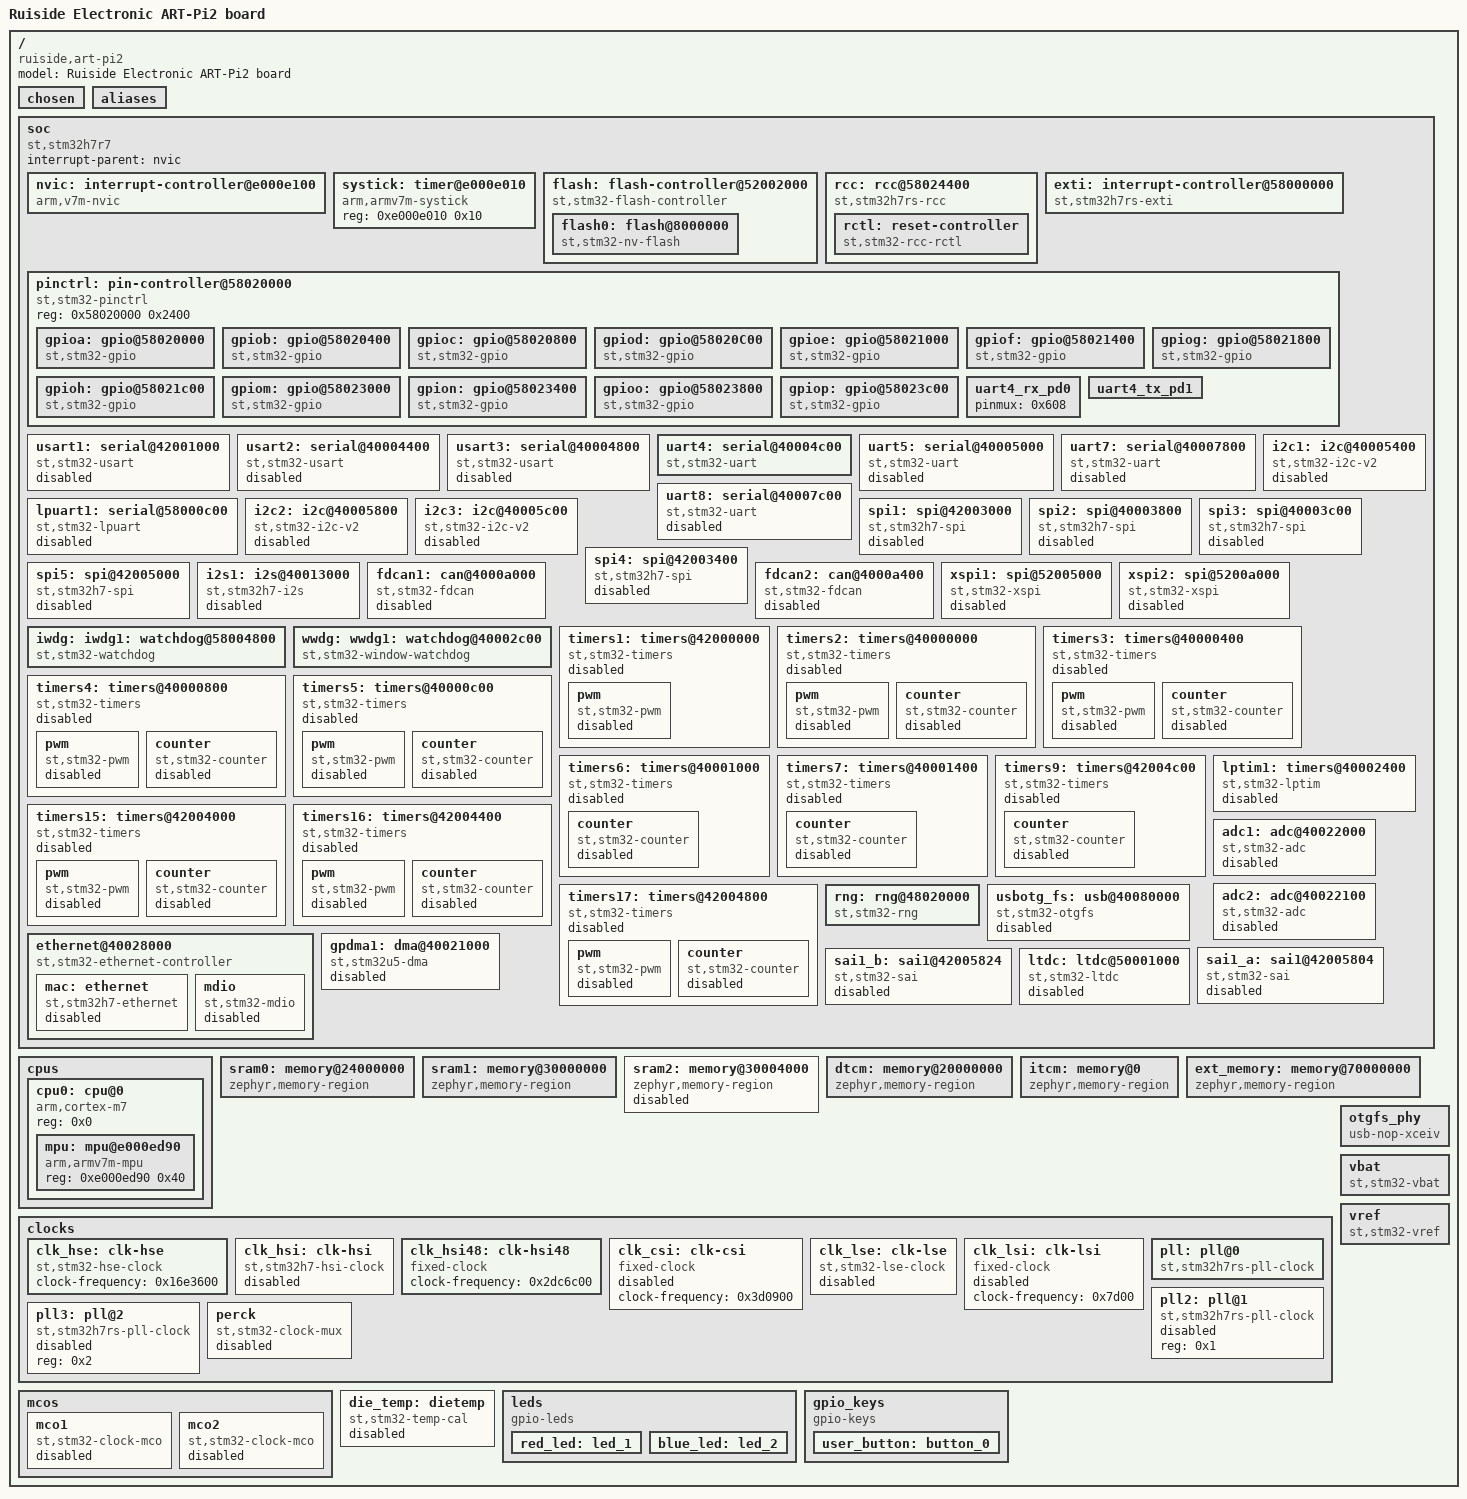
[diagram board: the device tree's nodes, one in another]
/dts-v1/;

/* node '/' defined in zephyr/dts/common/skeleton.dtsi:9 */
/ {
	#address-cells = < 0x1 >;                   /* in zephyr/dts/common/skeleton.dtsi:10 */
	#size-cells = < 0x1 >;                      /* in zephyr/dts/common/skeleton.dtsi:11 */
	model = "Ruiside Electronic ART-Pi2 board"; /* in zephyr/boards/ruiside/art_pi2/art_pi2.dts:13 */
	compatible = "ruiside,art-pi2";             /* in zephyr/boards/ruiside/art_pi2/art_pi2.dts:14 */

	/* node '/chosen' defined in zephyr/dts/common/skeleton.dtsi:13 */
	chosen {
		zephyr,entropy = &rng;            /* in zephyr/dts/arm/st/h7rs/stm32h7rs.dtsi:30 */
		zephyr,flash-controller = &flash; /* in zephyr/dts/arm/st/h7rs/stm32h7rs.dtsi:31 */
		zephyr,console = &uart4;          /* in zephyr/boards/ruiside/art_pi2/art_pi2.dts:17 */
		zephyr,shell-uart = &uart4;       /* in zephyr/boards/ruiside/art_pi2/art_pi2.dts:18 */
		zephyr,sram = &sram0;             /* in zephyr/boards/ruiside/art_pi2/art_pi2.dts:19 */
		zephyr,flash = &flash0;           /* in zephyr/boards/ruiside/art_pi2/art_pi2.dts:20 */
	};

	/* node '/aliases' defined in zephyr/dts/common/skeleton.dtsi:15 */
	aliases {
		led0 = &red_led;       /* in zephyr/boards/ruiside/art_pi2/art_pi2.dts:48 */
		led1 = &blue_led;      /* in zephyr/boards/ruiside/art_pi2/art_pi2.dts:49 */
		sw0 = &user_button;    /* in zephyr/boards/ruiside/art_pi2/art_pi2.dts:50 */
		watchdog0 = &iwdg;     /* in zephyr/boards/ruiside/art_pi2/art_pi2.dts:51 */
		die-temp0 = &die_temp; /* in zephyr/boards/ruiside/art_pi2/art_pi2.dts:52 */
		volt-sensor0 = &vref;  /* in zephyr/boards/ruiside/art_pi2/art_pi2.dts:53 */
		volt-sensor1 = &vbat;  /* in zephyr/boards/ruiside/art_pi2/art_pi2.dts:54 */
	};

	/* node '/soc' defined in zephyr/dts/arm/armv7-m.dtsi:6 */
	soc {
		#address-cells = < 0x1 >;     /* in zephyr/dts/arm/armv7-m.dtsi:7 */
		#size-cells = < 0x1 >;        /* in zephyr/dts/arm/armv7-m.dtsi:8 */
		interrupt-parent = < &nvic >; /* in zephyr/dts/arm/armv7-m.dtsi:10 */
		ranges;                       /* in zephyr/dts/arm/armv7-m.dtsi:11 */
		compatible = "st,stm32h7r7",
		             "st,stm32h7rs",
		             "simple-bus";    /* in zephyr/dts/arm/st/h7rs/stm32h7r7.dtsi:14 */

		/* node '/soc/interrupt-controller@e000e100' defined in zephyr/dts/arm/armv7-m.dtsi:13 */
		nvic: interrupt-controller@e000e100 {
			#address-cells = < 0x1 >;            /* in zephyr/dts/arm/armv7-m.dtsi:14 */
			compatible = "arm,v7m-nvic";         /* in zephyr/dts/arm/armv7-m.dtsi:15 */
			reg = < 0xe000e100 0xc00 >;          /* in zephyr/dts/arm/armv7-m.dtsi:16 */
			interrupt-controller;                /* in zephyr/dts/arm/armv7-m.dtsi:17 */
			#interrupt-cells = < 0x2 >;          /* in zephyr/dts/arm/armv7-m.dtsi:18 */
			arm,num-irq-priority-bits = < 0x4 >; /* in zephyr/dts/arm/st/h7rs/stm32h7rs.dtsi:985 */
			phandle = < 0x1 >;                   /* in zephyr/dts/arm/armv7-m.dtsi:10 */
		};

		/* node '/soc/timer@e000e010' defined in zephyr/dts/arm/armv7-m.dtsi:21 */
		systick: timer@e000e010 {
			compatible = "arm,armv7m-systick"; /* in zephyr/dts/arm/armv7-m.dtsi:22 */
			reg = < 0xe000e010 0x10 >;         /* in zephyr/dts/arm/armv7-m.dtsi:23 */
		};

		/* node '/soc/flash-controller@52002000' defined in zephyr/dts/arm/st/h7rs/stm32h7rs.dtsi:187 */
		flash: flash-controller@52002000 {
			compatible = "st,stm32-flash-controller",
			             "st,stm32h7-flash-controller"; /* in zephyr/dts/arm/st/h7rs/stm32h7rs.dtsi:188 */
			reg = < 0x52002000 0x400 >;                 /* in zephyr/dts/arm/st/h7rs/stm32h7rs.dtsi:189 */
			interrupts = < 0x8 0x0 >;                   /* in zephyr/dts/arm/st/h7rs/stm32h7rs.dtsi:190 */
			#address-cells = < 0x1 >;                   /* in zephyr/dts/arm/st/h7rs/stm32h7rs.dtsi:192 */
			#size-cells = < 0x1 >;                      /* in zephyr/dts/arm/st/h7rs/stm32h7rs.dtsi:193 */

			/* node '/soc/flash-controller@52002000/flash@8000000' defined in zephyr/dts/arm/st/h7rs/stm32h7rs.dtsi:195 */
			flash0: flash@8000000 {
				compatible = "st,stm32-nv-flash",
				             "soc-nv-flash";      /* in zephyr/dts/arm/st/h7rs/stm32h7rs.dtsi:196 */
				write-block-size = < 0x20 >;      /* in zephyr/dts/arm/st/h7rs/stm32h7rs.dtsi:197 */
				erase-block-size = < 0x2000 >;    /* in zephyr/dts/arm/st/h7rs/stm32h7rs.dtsi:198 */
				max-erase-time = < 0x3 >;         /* in zephyr/dts/arm/st/h7rs/stm32h7rs.dtsi:200 */
				reg = < 0x8000000 0x10000 >;      /* in zephyr/dts/arm/st/h7rs/stm32h7r7X8.dtsi:13 */
			};
		};

		/* node '/soc/rcc@58024400' defined in zephyr/dts/arm/st/h7rs/stm32h7rs.dtsi:204 */
		rcc: rcc@58024400 {
			compatible = "st,stm32h7rs-rcc"; /* in zephyr/dts/arm/st/h7rs/stm32h7rs.dtsi:205 */
			#clock-cells = < 0x2 >;          /* in zephyr/dts/arm/st/h7rs/stm32h7rs.dtsi:206 */
			reg = < 0x58024400 0x400 >;      /* in zephyr/dts/arm/st/h7rs/stm32h7rs.dtsi:207 */
			clocks = < &pll >;               /* in zephyr/boards/ruiside/art_pi2/art_pi2.dts:84 */
			clock-frequency = < 0xee6b280 >; /* in zephyr/boards/ruiside/art_pi2/art_pi2.dts:85 */
			dcpre = < 0x1 >;                 /* in zephyr/boards/ruiside/art_pi2/art_pi2.dts:86 */
			hpre = < 0x1 >;                  /* in zephyr/boards/ruiside/art_pi2/art_pi2.dts:87 */
			ppre1 = < 0x2 >;                 /* in zephyr/boards/ruiside/art_pi2/art_pi2.dts:88 */
			ppre2 = < 0x2 >;                 /* in zephyr/boards/ruiside/art_pi2/art_pi2.dts:89 */
			ppre4 = < 0x2 >;                 /* in zephyr/boards/ruiside/art_pi2/art_pi2.dts:90 */
			ppre5 = < 0x2 >;                 /* in zephyr/boards/ruiside/art_pi2/art_pi2.dts:91 */
			phandle = < 0x3 >;               /* in zephyr/dts/arm/st/h7rs/stm32h7rs.dtsi:221 */

			/* node '/soc/rcc@58024400/reset-controller' defined in zephyr/dts/arm/st/h7rs/stm32h7rs.dtsi:209 */
			rctl: reset-controller {
				compatible = "st,stm32-rcc-rctl"; /* in zephyr/dts/arm/st/h7rs/stm32h7rs.dtsi:210 */
				#reset-cells = < 0x1 >;           /* in zephyr/dts/arm/st/h7rs/stm32h7rs.dtsi:211 */
				phandle = < 0x4 >;                /* in zephyr/dts/arm/st/h7rs/stm32h7rs.dtsi:345 */
			};
		};

		/* node '/soc/interrupt-controller@58000000' defined in zephyr/dts/arm/st/h7rs/stm32h7rs.dtsi:215 */
		exti: interrupt-controller@58000000 {
			compatible = "st,stm32h7rs-exti",
			             "st,stm32-exti";     /* in zephyr/dts/arm/st/h7rs/stm32h7rs.dtsi:216 */
			interrupt-controller;             /* in zephyr/dts/arm/st/h7rs/stm32h7rs.dtsi:217 */
			#interrupt-cells = < 0x1 >;       /* in zephyr/dts/arm/st/h7rs/stm32h7rs.dtsi:218 */
			#address-cells = < 0x0 >;         /* in zephyr/dts/arm/st/h7rs/stm32h7rs.dtsi:219 */
			reg = < 0x58000000 0x400 >;       /* in zephyr/dts/arm/st/h7rs/stm32h7rs.dtsi:220 */
			clocks = < &rcc 0x154 0x2 >;      /* in zephyr/dts/arm/st/h7rs/stm32h7rs.dtsi:221 */
			num-lines = < 0x40 >;             /* in zephyr/dts/arm/st/h7rs/stm32h7rs.dtsi:223 */
			interrupts = < 0x10 0x0 >,
			             < 0x11 0x0 >,
			             < 0x12 0x0 >,
			             < 0x13 0x0 >,
			             < 0x14 0x0 >,
			             < 0x15 0x0 >,
			             < 0x16 0x0 >,
			             < 0x17 0x0 >,
			             < 0x18 0x0 >,
			             < 0x19 0x0 >,
			             < 0x1a 0x0 >,
			             < 0x1b 0x0 >,
			             < 0x1c 0x0 >,
			             < 0x1d 0x0 >,
			             < 0x1e 0x0 >,
			             < 0x1f 0x0 >;        /* in zephyr/dts/arm/st/h7rs/stm32h7rs.dtsi:224 */
			interrupt-names = "line0",
			                  "line1",
			                  "line2",
			                  "line3",
			                  "line4",
			                  "line5",
			                  "line6",
			                  "line7",
			                  "line8",
			                  "line9",
			                  "line10",
			                  "line11",
			                  "line12",
			                  "line13",
			                  "line14",
			                  "line15";       /* in zephyr/dts/arm/st/h7rs/stm32h7rs.dtsi:228 */
			line-ranges = < 0x0 0x1 >,
			              < 0x1 0x1 >,
			              < 0x2 0x1 >,
			              < 0x3 0x1 >,
			              < 0x4 0x1 >,
			              < 0x5 0x1 >,
			              < 0x6 0x1 >,
			              < 0x7 0x1 >,
			              < 0x8 0x1 >,
			              < 0x9 0x1 >,
			              < 0xa 0x1 >,
			              < 0xb 0x1 >,
			              < 0xc 0x1 >,
			              < 0xd 0x1 >,
			              < 0xe 0x1 >,
			              < 0xf 0x1 >;        /* in zephyr/dts/arm/st/h7rs/stm32h7rs.dtsi:232 */
		};

		/* node '/soc/pin-controller@58020000' defined in zephyr/dts/arm/st/h7rs/stm32h7rs.dtsi:238 */
		pinctrl: pin-controller@58020000 {
			compatible = "st,stm32-pinctrl"; /* in zephyr/dts/arm/st/h7rs/stm32h7rs.dtsi:239 */
			#address-cells = < 0x1 >;        /* in zephyr/dts/arm/st/h7rs/stm32h7rs.dtsi:240 */
			#size-cells = < 0x1 >;           /* in zephyr/dts/arm/st/h7rs/stm32h7rs.dtsi:241 */
			reg = < 0x58020000 0x2400 >;     /* in zephyr/dts/arm/st/h7rs/stm32h7rs.dtsi:242 */

			/* node '/soc/pin-controller@58020000/gpio@58020000' defined in zephyr/dts/arm/st/h7rs/stm32h7rs.dtsi:244 */
			gpioa: gpio@58020000 {
				compatible = "st,stm32-gpio"; /* in zephyr/dts/arm/st/h7rs/stm32h7rs.dtsi:245 */
				gpio-controller;              /* in zephyr/dts/arm/st/h7rs/stm32h7rs.dtsi:246 */
				#gpio-cells = < 0x2 >;        /* in zephyr/dts/arm/st/h7rs/stm32h7rs.dtsi:247 */
				reg = < 0x58020000 0x400 >;   /* in zephyr/dts/arm/st/h7rs/stm32h7rs.dtsi:248 */
				clocks = < &rcc 0x140 0x1 >;  /* in zephyr/dts/arm/st/h7rs/stm32h7rs.dtsi:249 */
			};

			/* node '/soc/pin-controller@58020000/gpio@58020400' defined in zephyr/dts/arm/st/h7rs/stm32h7rs.dtsi:252 */
			gpiob: gpio@58020400 {
				compatible = "st,stm32-gpio"; /* in zephyr/dts/arm/st/h7rs/stm32h7rs.dtsi:253 */
				gpio-controller;              /* in zephyr/dts/arm/st/h7rs/stm32h7rs.dtsi:254 */
				#gpio-cells = < 0x2 >;        /* in zephyr/dts/arm/st/h7rs/stm32h7rs.dtsi:255 */
				reg = < 0x58020400 0x400 >;   /* in zephyr/dts/arm/st/h7rs/stm32h7rs.dtsi:256 */
				clocks = < &rcc 0x140 0x2 >;  /* in zephyr/dts/arm/st/h7rs/stm32h7rs.dtsi:257 */
			};

			/* node '/soc/pin-controller@58020000/gpio@58020800' defined in zephyr/dts/arm/st/h7rs/stm32h7rs.dtsi:260 */
			gpioc: gpio@58020800 {
				compatible = "st,stm32-gpio"; /* in zephyr/dts/arm/st/h7rs/stm32h7rs.dtsi:261 */
				gpio-controller;              /* in zephyr/dts/arm/st/h7rs/stm32h7rs.dtsi:262 */
				#gpio-cells = < 0x2 >;        /* in zephyr/dts/arm/st/h7rs/stm32h7rs.dtsi:263 */
				reg = < 0x58020800 0x400 >;   /* in zephyr/dts/arm/st/h7rs/stm32h7rs.dtsi:264 */
				clocks = < &rcc 0x140 0x4 >;  /* in zephyr/dts/arm/st/h7rs/stm32h7rs.dtsi:265 */
				phandle = < 0xd >;            /* in zephyr/boards/ruiside/art_pi2/art_pi2.dts:42 */
			};

			/* node '/soc/pin-controller@58020000/gpio@58020C00' defined in zephyr/dts/arm/st/h7rs/stm32h7rs.dtsi:268 */
			gpiod: gpio@58020C00 {
				compatible = "st,stm32-gpio"; /* in zephyr/dts/arm/st/h7rs/stm32h7rs.dtsi:269 */
				gpio-controller;              /* in zephyr/dts/arm/st/h7rs/stm32h7rs.dtsi:270 */
				#gpio-cells = < 0x2 >;        /* in zephyr/dts/arm/st/h7rs/stm32h7rs.dtsi:271 */
				reg = < 0x58020c00 0x400 >;   /* in zephyr/dts/arm/st/h7rs/stm32h7rs.dtsi:272 */
				clocks = < &rcc 0x140 0x8 >;  /* in zephyr/dts/arm/st/h7rs/stm32h7rs.dtsi:273 */
			};

			/* node '/soc/pin-controller@58020000/gpio@58021000' defined in zephyr/dts/arm/st/h7rs/stm32h7rs.dtsi:276 */
			gpioe: gpio@58021000 {
				compatible = "st,stm32-gpio"; /* in zephyr/dts/arm/st/h7rs/stm32h7rs.dtsi:277 */
				gpio-controller;              /* in zephyr/dts/arm/st/h7rs/stm32h7rs.dtsi:278 */
				#gpio-cells = < 0x2 >;        /* in zephyr/dts/arm/st/h7rs/stm32h7rs.dtsi:279 */
				reg = < 0x58021000 0x400 >;   /* in zephyr/dts/arm/st/h7rs/stm32h7rs.dtsi:280 */
				clocks = < &rcc 0x140 0x10 >; /* in zephyr/dts/arm/st/h7rs/stm32h7rs.dtsi:281 */
			};

			/* node '/soc/pin-controller@58020000/gpio@58021400' defined in zephyr/dts/arm/st/h7rs/stm32h7rs.dtsi:284 */
			gpiof: gpio@58021400 {
				compatible = "st,stm32-gpio"; /* in zephyr/dts/arm/st/h7rs/stm32h7rs.dtsi:285 */
				gpio-controller;              /* in zephyr/dts/arm/st/h7rs/stm32h7rs.dtsi:286 */
				#gpio-cells = < 0x2 >;        /* in zephyr/dts/arm/st/h7rs/stm32h7rs.dtsi:287 */
				reg = < 0x58021400 0x400 >;   /* in zephyr/dts/arm/st/h7rs/stm32h7rs.dtsi:288 */
				clocks = < &rcc 0x140 0x20 >; /* in zephyr/dts/arm/st/h7rs/stm32h7rs.dtsi:289 */
			};

			/* node '/soc/pin-controller@58020000/gpio@58021800' defined in zephyr/dts/arm/st/h7rs/stm32h7rs.dtsi:292 */
			gpiog: gpio@58021800 {
				compatible = "st,stm32-gpio"; /* in zephyr/dts/arm/st/h7rs/stm32h7rs.dtsi:293 */
				gpio-controller;              /* in zephyr/dts/arm/st/h7rs/stm32h7rs.dtsi:294 */
				#gpio-cells = < 0x2 >;        /* in zephyr/dts/arm/st/h7rs/stm32h7rs.dtsi:295 */
				reg = < 0x58021800 0x400 >;   /* in zephyr/dts/arm/st/h7rs/stm32h7rs.dtsi:296 */
				clocks = < &rcc 0x140 0x40 >; /* in zephyr/dts/arm/st/h7rs/stm32h7rs.dtsi:297 */
			};

			/* node '/soc/pin-controller@58020000/gpio@58021c00' defined in zephyr/dts/arm/st/h7rs/stm32h7rs.dtsi:300 */
			gpioh: gpio@58021c00 {
				compatible = "st,stm32-gpio"; /* in zephyr/dts/arm/st/h7rs/stm32h7rs.dtsi:301 */
				gpio-controller;              /* in zephyr/dts/arm/st/h7rs/stm32h7rs.dtsi:302 */
				#gpio-cells = < 0x2 >;        /* in zephyr/dts/arm/st/h7rs/stm32h7rs.dtsi:303 */
				reg = < 0x58021c00 0x400 >;   /* in zephyr/dts/arm/st/h7rs/stm32h7rs.dtsi:304 */
				clocks = < &rcc 0x140 0x80 >; /* in zephyr/dts/arm/st/h7rs/stm32h7rs.dtsi:305 */
			};

			/* node '/soc/pin-controller@58020000/gpio@58023000' defined in zephyr/dts/arm/st/h7rs/stm32h7rs.dtsi:308 */
			gpiom: gpio@58023000 {
				compatible = "st,stm32-gpio";   /* in zephyr/dts/arm/st/h7rs/stm32h7rs.dtsi:309 */
				gpio-controller;                /* in zephyr/dts/arm/st/h7rs/stm32h7rs.dtsi:310 */
				#gpio-cells = < 0x2 >;          /* in zephyr/dts/arm/st/h7rs/stm32h7rs.dtsi:311 */
				reg = < 0x58023000 0x400 >;     /* in zephyr/dts/arm/st/h7rs/stm32h7rs.dtsi:312 */
				clocks = < &rcc 0x140 0x1000 >; /* in zephyr/dts/arm/st/h7rs/stm32h7rs.dtsi:313 */
			};

			/* node '/soc/pin-controller@58020000/gpio@58023400' defined in zephyr/dts/arm/st/h7rs/stm32h7rs.dtsi:316 */
			gpion: gpio@58023400 {
				compatible = "st,stm32-gpio";   /* in zephyr/dts/arm/st/h7rs/stm32h7rs.dtsi:317 */
				gpio-controller;                /* in zephyr/dts/arm/st/h7rs/stm32h7rs.dtsi:318 */
				#gpio-cells = < 0x2 >;          /* in zephyr/dts/arm/st/h7rs/stm32h7rs.dtsi:319 */
				reg = < 0x58023400 0x400 >;     /* in zephyr/dts/arm/st/h7rs/stm32h7rs.dtsi:320 */
				clocks = < &rcc 0x140 0x2000 >; /* in zephyr/dts/arm/st/h7rs/stm32h7rs.dtsi:321 */
			};

			/* node '/soc/pin-controller@58020000/gpio@58023800' defined in zephyr/dts/arm/st/h7rs/stm32h7rs.dtsi:324 */
			gpioo: gpio@58023800 {
				compatible = "st,stm32-gpio";   /* in zephyr/dts/arm/st/h7rs/stm32h7rs.dtsi:325 */
				gpio-controller;                /* in zephyr/dts/arm/st/h7rs/stm32h7rs.dtsi:326 */
				#gpio-cells = < 0x2 >;          /* in zephyr/dts/arm/st/h7rs/stm32h7rs.dtsi:327 */
				reg = < 0x58023800 0x400 >;     /* in zephyr/dts/arm/st/h7rs/stm32h7rs.dtsi:328 */
				clocks = < &rcc 0x140 0x4000 >; /* in zephyr/dts/arm/st/h7rs/stm32h7rs.dtsi:329 */
				phandle = < 0xc >;              /* in zephyr/boards/ruiside/art_pi2/art_pi2.dts:27 */
			};

			/* node '/soc/pin-controller@58020000/gpio@58023c00' defined in zephyr/dts/arm/st/h7rs/stm32h7rs.dtsi:332 */
			gpiop: gpio@58023c00 {
				compatible = "st,stm32-gpio";   /* in zephyr/dts/arm/st/h7rs/stm32h7rs.dtsi:333 */
				gpio-controller;                /* in zephyr/dts/arm/st/h7rs/stm32h7rs.dtsi:334 */
				#gpio-cells = < 0x2 >;          /* in zephyr/dts/arm/st/h7rs/stm32h7rs.dtsi:335 */
				reg = < 0x58023c00 0x400 >;     /* in zephyr/dts/arm/st/h7rs/stm32h7rs.dtsi:336 */
				clocks = < &rcc 0x140 0x8000 >; /* in zephyr/dts/arm/st/h7rs/stm32h7rs.dtsi:337 */
			};

			/* node '/soc/pin-controller@58020000/uart4_rx_pd0' defined in modules/hal/stm32/dts/st/h7/stm32h7r7l8hxh-pinctrl.dtsi:3787 */
			uart4_rx_pd0: uart4_rx_pd0 {
				pinmux = < 0x608 >; /* in modules/hal/stm32/dts/st/h7/stm32h7r7l8hxh-pinctrl.dtsi:3788 */
				phandle = < 0x6 >;  /* in zephyr/boards/ruiside/art_pi2/art_pi2.dts:95 */
			};

			/* node '/soc/pin-controller@58020000/uart4_tx_pd1' defined in modules/hal/stm32/dts/st/h7/stm32h7r7l8hxh-pinctrl.dtsi:3899 */
			uart4_tx_pd1: uart4_tx_pd1 {
				pinmux = < 0x628 >; /* in modules/hal/stm32/dts/st/h7/stm32h7r7l8hxh-pinctrl.dtsi:3900 */
				bias-pull-up;       /* in modules/hal/stm32/dts/st/h7/stm32h7r7l8hxh-pinctrl.dtsi:3901 */
				phandle = < 0x5 >;  /* in zephyr/boards/ruiside/art_pi2/art_pi2.dts:95 */
			};
		};

		/* node '/soc/serial@42001000' defined in zephyr/dts/arm/st/h7rs/stm32h7rs.dtsi:341 */
		usart1: serial@42001000 {
			compatible = "st,stm32-usart",
			             "st,stm32-uart";  /* in zephyr/dts/arm/st/h7rs/stm32h7rs.dtsi:342 */
			reg = < 0x42001000 0x400 >;    /* in zephyr/dts/arm/st/h7rs/stm32h7rs.dtsi:343 */
			clocks = < &rcc 0x150 0x10 >;  /* in zephyr/dts/arm/st/h7rs/stm32h7rs.dtsi:344 */
			resets = < &rctl 0x1304 >;     /* in zephyr/dts/arm/st/h7rs/stm32h7rs.dtsi:345 */
			interrupts = < 0x52 0x0 >;     /* in zephyr/dts/arm/st/h7rs/stm32h7rs.dtsi:346 */
			status = "disabled";           /* in zephyr/dts/arm/st/h7rs/stm32h7rs.dtsi:347 */
		};

		/* node '/soc/serial@40004400' defined in zephyr/dts/arm/st/h7rs/stm32h7rs.dtsi:350 */
		usart2: serial@40004400 {
			compatible = "st,stm32-usart",
			             "st,stm32-uart";    /* in zephyr/dts/arm/st/h7rs/stm32h7rs.dtsi:351 */
			reg = < 0x40004400 0x400 >;      /* in zephyr/dts/arm/st/h7rs/stm32h7rs.dtsi:352 */
			clocks = < &rcc 0x148 0x20000 >; /* in zephyr/dts/arm/st/h7rs/stm32h7rs.dtsi:353 */
			resets = < &rctl 0x1211 >;       /* in zephyr/dts/arm/st/h7rs/stm32h7rs.dtsi:354 */
			interrupts = < 0x53 0x0 >;       /* in zephyr/dts/arm/st/h7rs/stm32h7rs.dtsi:355 */
			status = "disabled";             /* in zephyr/dts/arm/st/h7rs/stm32h7rs.dtsi:356 */
		};

		/* node '/soc/serial@40004800' defined in zephyr/dts/arm/st/h7rs/stm32h7rs.dtsi:359 */
		usart3: serial@40004800 {
			compatible = "st,stm32-usart",
			             "st,stm32-uart";    /* in zephyr/dts/arm/st/h7rs/stm32h7rs.dtsi:360 */
			reg = < 0x40004800 0x400 >;      /* in zephyr/dts/arm/st/h7rs/stm32h7rs.dtsi:361 */
			clocks = < &rcc 0x148 0x40000 >; /* in zephyr/dts/arm/st/h7rs/stm32h7rs.dtsi:362 */
			resets = < &rctl 0x1212 >;       /* in zephyr/dts/arm/st/h7rs/stm32h7rs.dtsi:363 */
			interrupts = < 0x54 0x0 >;       /* in zephyr/dts/arm/st/h7rs/stm32h7rs.dtsi:364 */
			status = "disabled";             /* in zephyr/dts/arm/st/h7rs/stm32h7rs.dtsi:365 */
		};

		/* node '/soc/serial@40004c00' defined in zephyr/dts/arm/st/h7rs/stm32h7rs.dtsi:368 */
		uart4: serial@40004c00 {
			compatible = "st,stm32-uart";                /* in zephyr/dts/arm/st/h7rs/stm32h7rs.dtsi:369 */
			reg = < 0x40004c00 0x400 >;                  /* in zephyr/dts/arm/st/h7rs/stm32h7rs.dtsi:370 */
			clocks = < &rcc 0x148 0x80000 >;             /* in zephyr/dts/arm/st/h7rs/stm32h7rs.dtsi:371 */
			resets = < &rctl 0x1213 >;                   /* in zephyr/dts/arm/st/h7rs/stm32h7rs.dtsi:372 */
			interrupts = < 0x55 0x0 >;                   /* in zephyr/dts/arm/st/h7rs/stm32h7rs.dtsi:373 */
			pinctrl-0 = < &uart4_tx_pd1 &uart4_rx_pd0 >; /* in zephyr/boards/ruiside/art_pi2/art_pi2.dts:95 */
			pinctrl-names = "default";                   /* in zephyr/boards/ruiside/art_pi2/art_pi2.dts:96 */
			current-speed = < 0x1c200 >;                 /* in zephyr/boards/ruiside/art_pi2/art_pi2.dts:97 */
			status = "okay";                             /* in zephyr/boards/ruiside/art_pi2/art_pi2.dts:98 */
		};

		/* node '/soc/serial@40005000' defined in zephyr/dts/arm/st/h7rs/stm32h7rs.dtsi:377 */
		uart5: serial@40005000 {
			compatible = "st,stm32-uart";     /* in zephyr/dts/arm/st/h7rs/stm32h7rs.dtsi:378 */
			reg = < 0x40005000 0x400 >;       /* in zephyr/dts/arm/st/h7rs/stm32h7rs.dtsi:379 */
			clocks = < &rcc 0x148 0x100000 >; /* in zephyr/dts/arm/st/h7rs/stm32h7rs.dtsi:380 */
			resets = < &rctl 0x1214 >;        /* in zephyr/dts/arm/st/h7rs/stm32h7rs.dtsi:381 */
			interrupts = < 0x56 0x0 >;        /* in zephyr/dts/arm/st/h7rs/stm32h7rs.dtsi:382 */
			status = "disabled";              /* in zephyr/dts/arm/st/h7rs/stm32h7rs.dtsi:383 */
		};

		/* node '/soc/serial@40007800' defined in zephyr/dts/arm/st/h7rs/stm32h7rs.dtsi:386 */
		uart7: serial@40007800 {
			compatible = "st,stm32-uart";       /* in zephyr/dts/arm/st/h7rs/stm32h7rs.dtsi:387 */
			reg = < 0x40007800 0x400 >;         /* in zephyr/dts/arm/st/h7rs/stm32h7rs.dtsi:388 */
			clocks = < &rcc 0x148 0x40000000 >; /* in zephyr/dts/arm/st/h7rs/stm32h7rs.dtsi:389 */
			resets = < &rctl 0x121e >;          /* in zephyr/dts/arm/st/h7rs/stm32h7rs.dtsi:390 */
			interrupts = < 0x57 0x0 >;          /* in zephyr/dts/arm/st/h7rs/stm32h7rs.dtsi:391 */
			status = "disabled";                /* in zephyr/dts/arm/st/h7rs/stm32h7rs.dtsi:392 */
		};

		/* node '/soc/serial@40007c00' defined in zephyr/dts/arm/st/h7rs/stm32h7rs.dtsi:395 */
		uart8: serial@40007c00 {
			compatible = "st,stm32-uart";       /* in zephyr/dts/arm/st/h7rs/stm32h7rs.dtsi:396 */
			reg = < 0x40007c00 0x400 >;         /* in zephyr/dts/arm/st/h7rs/stm32h7rs.dtsi:397 */
			clocks = < &rcc 0x148 0x80000000 >; /* in zephyr/dts/arm/st/h7rs/stm32h7rs.dtsi:398 */
			resets = < &rctl 0x121f >;          /* in zephyr/dts/arm/st/h7rs/stm32h7rs.dtsi:399 */
			interrupts = < 0x58 0x0 >;          /* in zephyr/dts/arm/st/h7rs/stm32h7rs.dtsi:400 */
			status = "disabled";                /* in zephyr/dts/arm/st/h7rs/stm32h7rs.dtsi:401 */
		};

		/* node '/soc/serial@58000c00' defined in zephyr/dts/arm/st/h7rs/stm32h7rs.dtsi:404 */
		lpuart1: serial@58000c00 {
			compatible = "st,stm32-lpuart",
			             "st,stm32-uart";   /* in zephyr/dts/arm/st/h7rs/stm32h7rs.dtsi:405 */
			reg = < 0x58000c00 0x400 >;     /* in zephyr/dts/arm/st/h7rs/stm32h7rs.dtsi:406 */
			clocks = < &rcc 0x154 0x8 >;    /* in zephyr/dts/arm/st/h7rs/stm32h7rs.dtsi:407 */
			resets = < &rctl 0x1383 >;      /* in zephyr/dts/arm/st/h7rs/stm32h7rs.dtsi:408 */
			interrupts = < 0x83 0x0 >;      /* in zephyr/dts/arm/st/h7rs/stm32h7rs.dtsi:409 */
			status = "disabled";            /* in zephyr/dts/arm/st/h7rs/stm32h7rs.dtsi:410 */
		};

		/* node '/soc/i2c@40005400' defined in zephyr/dts/arm/st/h7rs/stm32h7rs.dtsi:413 */
		i2c1: i2c@40005400 {
			compatible = "st,stm32-i2c-v2";   /* in zephyr/dts/arm/st/h7rs/stm32h7rs.dtsi:414 */
			clock-frequency = < 0x186a0 >;    /* in zephyr/dts/arm/st/h7rs/stm32h7rs.dtsi:415 */
			#address-cells = < 0x1 >;         /* in zephyr/dts/arm/st/h7rs/stm32h7rs.dtsi:416 */
			#size-cells = < 0x0 >;            /* in zephyr/dts/arm/st/h7rs/stm32h7rs.dtsi:417 */
			reg = < 0x40005400 0x400 >;       /* in zephyr/dts/arm/st/h7rs/stm32h7rs.dtsi:418 */
			clocks = < &rcc 0x148 0x200000 >; /* in zephyr/dts/arm/st/h7rs/stm32h7rs.dtsi:419 */
			interrupts = < 0x4c 0x0 >,
			             < 0x4d 0x0 >;        /* in zephyr/dts/arm/st/h7rs/stm32h7rs.dtsi:420 */
			interrupt-names = "event",
			                  "error";        /* in zephyr/dts/arm/st/h7rs/stm32h7rs.dtsi:421 */
			status = "disabled";              /* in zephyr/dts/arm/st/h7rs/stm32h7rs.dtsi:422 */
		};

		/* node '/soc/i2c@40005800' defined in zephyr/dts/arm/st/h7rs/stm32h7rs.dtsi:425 */
		i2c2: i2c@40005800 {
			compatible = "st,stm32-i2c-v2";   /* in zephyr/dts/arm/st/h7rs/stm32h7rs.dtsi:426 */
			clock-frequency = < 0x186a0 >;    /* in zephyr/dts/arm/st/h7rs/stm32h7rs.dtsi:427 */
			#address-cells = < 0x1 >;         /* in zephyr/dts/arm/st/h7rs/stm32h7rs.dtsi:428 */
			#size-cells = < 0x0 >;            /* in zephyr/dts/arm/st/h7rs/stm32h7rs.dtsi:429 */
			reg = < 0x40005800 0x400 >;       /* in zephyr/dts/arm/st/h7rs/stm32h7rs.dtsi:430 */
			clocks = < &rcc 0x148 0x400000 >; /* in zephyr/dts/arm/st/h7rs/stm32h7rs.dtsi:431 */
			interrupts = < 0x4e 0x0 >,
			             < 0x4f 0x0 >;        /* in zephyr/dts/arm/st/h7rs/stm32h7rs.dtsi:432 */
			interrupt-names = "event",
			                  "error";        /* in zephyr/dts/arm/st/h7rs/stm32h7rs.dtsi:433 */
			status = "disabled";              /* in zephyr/dts/arm/st/h7rs/stm32h7rs.dtsi:434 */
		};

		/* node '/soc/i2c@40005c00' defined in zephyr/dts/arm/st/h7rs/stm32h7rs.dtsi:437 */
		i2c3: i2c@40005c00 {
			compatible = "st,stm32-i2c-v2";   /* in zephyr/dts/arm/st/h7rs/stm32h7rs.dtsi:438 */
			clock-frequency = < 0x186a0 >;    /* in zephyr/dts/arm/st/h7rs/stm32h7rs.dtsi:439 */
			#address-cells = < 0x1 >;         /* in zephyr/dts/arm/st/h7rs/stm32h7rs.dtsi:440 */
			#size-cells = < 0x0 >;            /* in zephyr/dts/arm/st/h7rs/stm32h7rs.dtsi:441 */
			reg = < 0x40005c00 0x400 >;       /* in zephyr/dts/arm/st/h7rs/stm32h7rs.dtsi:442 */
			clocks = < &rcc 0x148 0x800000 >; /* in zephyr/dts/arm/st/h7rs/stm32h7rs.dtsi:443 */
			interrupts = < 0x50 0x0 >,
			             < 0x51 0x0 >;        /* in zephyr/dts/arm/st/h7rs/stm32h7rs.dtsi:444 */
			interrupt-names = "event",
			                  "error";        /* in zephyr/dts/arm/st/h7rs/stm32h7rs.dtsi:445 */
			status = "disabled";              /* in zephyr/dts/arm/st/h7rs/stm32h7rs.dtsi:446 */
		};

		/* node '/soc/spi@42003000' defined in zephyr/dts/arm/st/h7rs/stm32h7rs.dtsi:449 */
		spi1: spi@42003000 {
			compatible = "st,stm32h7-spi",
			             "st,stm32-spi-fifo",
			             "st,stm32-spi";      /* in zephyr/dts/arm/st/h7rs/stm32h7rs.dtsi:450 */
			#address-cells = < 0x1 >;         /* in zephyr/dts/arm/st/h7rs/stm32h7rs.dtsi:451 */
			#size-cells = < 0x0 >;            /* in zephyr/dts/arm/st/h7rs/stm32h7rs.dtsi:452 */
			reg = < 0x42003000 0x400 >;       /* in zephyr/dts/arm/st/h7rs/stm32h7rs.dtsi:453 */
			clocks = < &rcc 0x150 0x1000 >,
			         < &rcc 0x9 0x480054 >;   /* in zephyr/dts/arm/st/h7rs/stm32h7rs.dtsi:454 */
			interrupts = < 0x3a 0x0 >;        /* in zephyr/dts/arm/st/h7rs/stm32h7rs.dtsi:456 */
			status = "disabled";              /* in zephyr/dts/arm/st/h7rs/stm32h7rs.dtsi:457 */
		};

		/* node '/soc/spi@40003800' defined in zephyr/dts/arm/st/h7rs/stm32h7rs.dtsi:460 */
		spi2: spi@40003800 {
			compatible = "st,stm32h7-spi",
			             "st,stm32-spi-fifo",
			             "st,stm32-spi";      /* in zephyr/dts/arm/st/h7rs/stm32h7rs.dtsi:461 */
			#address-cells = < 0x1 >;         /* in zephyr/dts/arm/st/h7rs/stm32h7rs.dtsi:462 */
			#size-cells = < 0x0 >;            /* in zephyr/dts/arm/st/h7rs/stm32h7rs.dtsi:463 */
			reg = < 0x40003800 0x400 >;       /* in zephyr/dts/arm/st/h7rs/stm32h7rs.dtsi:464 */
			clocks = < &rcc 0x148 0x4000 >,
			         < &rcc 0x9 0x440050 >;   /* in zephyr/dts/arm/st/h7rs/stm32h7rs.dtsi:465 */
			interrupts = < 0x3b 0x0 >;        /* in zephyr/dts/arm/st/h7rs/stm32h7rs.dtsi:467 */
			status = "disabled";              /* in zephyr/dts/arm/st/h7rs/stm32h7rs.dtsi:468 */
		};

		/* node '/soc/spi@40003c00' defined in zephyr/dts/arm/st/h7rs/stm32h7rs.dtsi:471 */
		spi3: spi@40003c00 {
			compatible = "st,stm32h7-spi",
			             "st,stm32-spi-fifo",
			             "st,stm32-spi";      /* in zephyr/dts/arm/st/h7rs/stm32h7rs.dtsi:472 */
			#address-cells = < 0x1 >;         /* in zephyr/dts/arm/st/h7rs/stm32h7rs.dtsi:473 */
			#size-cells = < 0x0 >;            /* in zephyr/dts/arm/st/h7rs/stm32h7rs.dtsi:474 */
			reg = < 0x40003c00 0x400 >;       /* in zephyr/dts/arm/st/h7rs/stm32h7rs.dtsi:475 */
			clocks = < &rcc 0x148 0x8000 >,
			         < &rcc 0x9 0x440050 >;   /* in zephyr/dts/arm/st/h7rs/stm32h7rs.dtsi:476 */
			interrupts = < 0x3c 0x0 >;        /* in zephyr/dts/arm/st/h7rs/stm32h7rs.dtsi:478 */
			status = "disabled";              /* in zephyr/dts/arm/st/h7rs/stm32h7rs.dtsi:479 */
		};

		/* node '/soc/spi@42003400' defined in zephyr/dts/arm/st/h7rs/stm32h7rs.dtsi:482 */
		spi4: spi@42003400 {
			compatible = "st,stm32h7-spi",
			             "st,stm32-spi-fifo",
			             "st,stm32-spi";      /* in zephyr/dts/arm/st/h7rs/stm32h7rs.dtsi:483 */
			#address-cells = < 0x1 >;         /* in zephyr/dts/arm/st/h7rs/stm32h7rs.dtsi:484 */
			#size-cells = < 0x0 >;            /* in zephyr/dts/arm/st/h7rs/stm32h7rs.dtsi:485 */
			reg = < 0x42003400 0x400 >;       /* in zephyr/dts/arm/st/h7rs/stm32h7rs.dtsi:486 */
			clocks = < &rcc 0x150 0x2000 >;   /* in zephyr/dts/arm/st/h7rs/stm32h7rs.dtsi:487 */
			interrupts = < 0x3d 0x0 >;        /* in zephyr/dts/arm/st/h7rs/stm32h7rs.dtsi:488 */
			status = "disabled";              /* in zephyr/dts/arm/st/h7rs/stm32h7rs.dtsi:489 */
		};

		/* node '/soc/spi@42005000' defined in zephyr/dts/arm/st/h7rs/stm32h7rs.dtsi:492 */
		spi5: spi@42005000 {
			compatible = "st,stm32h7-spi",
			             "st,stm32-spi-fifo",
			             "st,stm32-spi";      /* in zephyr/dts/arm/st/h7rs/stm32h7rs.dtsi:493 */
			#address-cells = < 0x1 >;         /* in zephyr/dts/arm/st/h7rs/stm32h7rs.dtsi:494 */
			#size-cells = < 0x0 >;            /* in zephyr/dts/arm/st/h7rs/stm32h7rs.dtsi:495 */
			reg = < 0x42005000 0x400 >;       /* in zephyr/dts/arm/st/h7rs/stm32h7rs.dtsi:496 */
			clocks = < &rcc 0x150 0x100000 >; /* in zephyr/dts/arm/st/h7rs/stm32h7rs.dtsi:497 */
			interrupts = < 0x3e 0x0 >;        /* in zephyr/dts/arm/st/h7rs/stm32h7rs.dtsi:498 */
			status = "disabled";              /* in zephyr/dts/arm/st/h7rs/stm32h7rs.dtsi:499 */
		};

		/* node '/soc/i2s@40013000' defined in zephyr/dts/arm/st/h7rs/stm32h7rs.dtsi:502 */
		i2s1: i2s@40013000 {
			compatible = "st,stm32h7-i2s",
			             "st,stm32-i2s";    /* in zephyr/dts/arm/st/h7rs/stm32h7rs.dtsi:503 */
			#address-cells = < 0x1 >;       /* in zephyr/dts/arm/st/h7rs/stm32h7rs.dtsi:504 */
			#size-cells = < 0x0 >;          /* in zephyr/dts/arm/st/h7rs/stm32h7rs.dtsi:505 */
			reg = < 0x40013000 0x400 >;     /* in zephyr/dts/arm/st/h7rs/stm32h7rs.dtsi:506 */
			clocks = < &rcc 0x150 0x1000 >,
			         < &rcc 0x9 0x480054 >; /* in zephyr/dts/arm/st/h7rs/stm32h7rs.dtsi:507 */
			interrupts = < 0x23 0x3 >;      /* in zephyr/dts/arm/st/h7rs/stm32h7rs.dtsi:509 */
			status = "disabled";            /* in zephyr/dts/arm/st/h7rs/stm32h7rs.dtsi:510 */
		};

		/* node '/soc/can@4000a000' defined in zephyr/dts/arm/st/h7rs/stm32h7rs.dtsi:513 */
		fdcan1: can@4000a000 {
			compatible = "st,stm32-fdcan";                         /* in zephyr/dts/arm/st/h7rs/stm32h7rs.dtsi:514 */
			reg = < 0x4000a000 0x400 >,
			      < 0x4000ac00 0x350 >;                            /* in zephyr/dts/arm/st/h7rs/stm32h7rs.dtsi:515 */
			reg-names = "m_can",
			            "message_ram";                             /* in zephyr/dts/arm/st/h7rs/stm32h7rs.dtsi:516 */
			clocks = < &rcc 0x14c 0x100 >,
			         < &rcc 0x4 0x360050 >;                        /* in zephyr/dts/arm/st/h7rs/stm32h7rs.dtsi:518 */
			interrupts = < 0x98 0x0 >,
			             < 0x99 0x0 >;                             /* in zephyr/dts/arm/st/h7rs/stm32h7rs.dtsi:520 */
			interrupt-names = "int0",
			                  "int1";                              /* in zephyr/dts/arm/st/h7rs/stm32h7rs.dtsi:521 */
			bosch,mram-cfg = < 0x0 0x1c 0x8 0x3 0x3 0x0 0x3 0x3 >; /* in zephyr/dts/arm/st/h7rs/stm32h7rs.dtsi:522 */
			status = "disabled";                                   /* in zephyr/dts/arm/st/h7rs/stm32h7rs.dtsi:523 */
		};

		/* node '/soc/can@4000a400' defined in zephyr/dts/arm/st/h7rs/stm32h7rs.dtsi:526 */
		fdcan2: can@4000a400 {
			compatible = "st,stm32-fdcan";                           /* in zephyr/dts/arm/st/h7rs/stm32h7rs.dtsi:527 */
			reg = < 0x4000a400 0x400 >,
			      < 0x4000ac00 0x6a0 >;                              /* in zephyr/dts/arm/st/h7rs/stm32h7rs.dtsi:528 */
			reg-names = "m_can",
			            "message_ram";                               /* in zephyr/dts/arm/st/h7rs/stm32h7rs.dtsi:529 */
			clocks = < &rcc 0x14c 0x100 >,
			         < &rcc 0x4 0x360050 >;                          /* in zephyr/dts/arm/st/h7rs/stm32h7rs.dtsi:531 */
			interrupts = < 0x9a 0x0 >,
			             < 0x9b 0x0 >;                               /* in zephyr/dts/arm/st/h7rs/stm32h7rs.dtsi:533 */
			interrupt-names = "int0",
			                  "int1";                                /* in zephyr/dts/arm/st/h7rs/stm32h7rs.dtsi:534 */
			bosch,mram-cfg = < 0x350 0x1c 0x8 0x3 0x3 0x0 0x3 0x3 >; /* in zephyr/dts/arm/st/h7rs/stm32h7rs.dtsi:535 */
			status = "disabled";                                     /* in zephyr/dts/arm/st/h7rs/stm32h7rs.dtsi:536 */
		};

		/* node '/soc/spi@52005000' defined in zephyr/dts/arm/st/h7rs/stm32h7rs.dtsi:539 */
		xspi1: spi@52005000 {
			compatible = "st,stm32-xspi";    /* in zephyr/dts/arm/st/h7rs/stm32h7rs.dtsi:540 */
			reg = < 0x52005000 0x1000 >,
			      < 0x90000000 0x10000000 >; /* in zephyr/dts/arm/st/h7rs/stm32h7rs.dtsi:541 */
			interrupts = < 0x69 0x0 >;       /* in zephyr/dts/arm/st/h7rs/stm32h7rs.dtsi:542 */
			clock-names = "xspix";           /* in zephyr/dts/arm/st/h7rs/stm32h7rs.dtsi:543 */
			clocks = < &rcc 0x134 0x20 >;    /* in zephyr/dts/arm/st/h7rs/stm32h7rs.dtsi:544 */
			#address-cells = < 0x1 >;        /* in zephyr/dts/arm/st/h7rs/stm32h7rs.dtsi:545 */
			#size-cells = < 0x0 >;           /* in zephyr/dts/arm/st/h7rs/stm32h7rs.dtsi:546 */
			status = "disabled";             /* in zephyr/dts/arm/st/h7rs/stm32h7rs.dtsi:547 */
		};

		/* node '/soc/spi@5200a000' defined in zephyr/dts/arm/st/h7rs/stm32h7rs.dtsi:550 */
		xspi2: spi@5200a000 {
			compatible = "st,stm32-xspi";    /* in zephyr/dts/arm/st/h7rs/stm32h7rs.dtsi:551 */
			reg = < 0x5200a000 0x1000 >,
			      < 0x70000000 0x10000000 >; /* in zephyr/dts/arm/st/h7rs/stm32h7rs.dtsi:552 */
			interrupts = < 0x6a 0x0 >;       /* in zephyr/dts/arm/st/h7rs/stm32h7rs.dtsi:553 */
			clock-names = "xspix";           /* in zephyr/dts/arm/st/h7rs/stm32h7rs.dtsi:554 */
			clocks = < &rcc 0x134 0x1000 >;  /* in zephyr/dts/arm/st/h7rs/stm32h7rs.dtsi:555 */
			#address-cells = < 0x1 >;        /* in zephyr/dts/arm/st/h7rs/stm32h7rs.dtsi:556 */
			#size-cells = < 0x0 >;           /* in zephyr/dts/arm/st/h7rs/stm32h7rs.dtsi:557 */
			status = "disabled";             /* in zephyr/dts/arm/st/h7rs/stm32h7rs.dtsi:558 */
		};

		/* node '/soc/watchdog@58004800' defined in zephyr/dts/arm/st/h7rs/stm32h7rs.dtsi:561 */
		iwdg: iwdg1: watchdog@58004800 {
			compatible = "st,stm32-watchdog"; /* in zephyr/dts/arm/st/h7rs/stm32h7rs.dtsi:562 */
			reg = < 0x58004800 0x400 >;       /* in zephyr/dts/arm/st/h7rs/stm32h7rs.dtsi:563 */
			interrupts = < 0x3 0x0 >;         /* in zephyr/dts/arm/st/h7rs/stm32h7rs.dtsi:564 */
			status = "okay";                  /* in zephyr/boards/ruiside/art_pi2/art_pi2.dts:106 */
		};

		/* node '/soc/watchdog@40002c00' defined in zephyr/dts/arm/st/h7rs/stm32h7rs.dtsi:568 */
		wwdg: wwdg1: watchdog@40002c00 {
			compatible = "st,stm32-window-watchdog"; /* in zephyr/dts/arm/st/h7rs/stm32h7rs.dtsi:569 */
			reg = < 0x40002c00 0x1000 >;             /* in zephyr/dts/arm/st/h7rs/stm32h7rs.dtsi:570 */
			clocks = < &rcc 0x148 0x800 >;           /* in zephyr/dts/arm/st/h7rs/stm32h7rs.dtsi:571 */
			interrupts = < 0x4 0x7 >;                /* in zephyr/dts/arm/st/h7rs/stm32h7rs.dtsi:572 */
			status = "okay";                         /* in zephyr/boards/ruiside/art_pi2/art_pi2.dts:110 */
		};

		/* node '/soc/timers@42000000' defined in zephyr/dts/arm/st/h7rs/stm32h7rs.dtsi:576 */
		timers1: timers@42000000 {
			compatible = "st,stm32-timers"; /* in zephyr/dts/arm/st/h7rs/stm32h7rs.dtsi:577 */
			reg = < 0x42000000 0x400 >;     /* in zephyr/dts/arm/st/h7rs/stm32h7rs.dtsi:578 */
			clocks = < &rcc 0x150 0x1 >,
			         < &rcc 0x1c 0xff >;    /* in zephyr/dts/arm/st/h7rs/stm32h7rs.dtsi:579 */
			resets = < &rctl 0x1300 >;      /* in zephyr/dts/arm/st/h7rs/stm32h7rs.dtsi:581 */
			interrupts = < 0x2f 0x0 >,
			             < 0x30 0x0 >,
			             < 0x31 0x0 >,
			             < 0x32 0x0 >;      /* in zephyr/dts/arm/st/h7rs/stm32h7rs.dtsi:582 */
			interrupt-names = "brk",
			                  "up",
			                  "trgcom",
			                  "cc";         /* in zephyr/dts/arm/st/h7rs/stm32h7rs.dtsi:583 */
			st,prescaler = < 0x0 >;         /* in zephyr/dts/arm/st/h7rs/stm32h7rs.dtsi:584 */
			status = "disabled";            /* in zephyr/dts/arm/st/h7rs/stm32h7rs.dtsi:585 */

			/* node '/soc/timers@42000000/pwm' defined in zephyr/dts/arm/st/h7rs/stm32h7rs.dtsi:587 */
			pwm {
				compatible = "st,stm32-pwm"; /* in zephyr/dts/arm/st/h7rs/stm32h7rs.dtsi:588 */
				status = "disabled";         /* in zephyr/dts/arm/st/h7rs/stm32h7rs.dtsi:589 */
				#pwm-cells = < 0x3 >;        /* in zephyr/dts/arm/st/h7rs/stm32h7rs.dtsi:590 */
			};
		};

		/* node '/soc/timers@40000000' defined in zephyr/dts/arm/st/h7rs/stm32h7rs.dtsi:594 */
		timers2: timers@40000000 {
			compatible = "st,stm32-timers"; /* in zephyr/dts/arm/st/h7rs/stm32h7rs.dtsi:595 */
			reg = < 0x40000000 0x400 >;     /* in zephyr/dts/arm/st/h7rs/stm32h7rs.dtsi:596 */
			clocks = < &rcc 0x148 0x1 >,
			         < &rcc 0x1b 0xff >;    /* in zephyr/dts/arm/st/h7rs/stm32h7rs.dtsi:597 */
			resets = < &rctl 0x1200 >;      /* in zephyr/dts/arm/st/h7rs/stm32h7rs.dtsi:599 */
			interrupts = < 0x33 0x0 >;      /* in zephyr/dts/arm/st/h7rs/stm32h7rs.dtsi:600 */
			interrupt-names = "global";     /* in zephyr/dts/arm/st/h7rs/stm32h7rs.dtsi:601 */
			st,prescaler = < 0x0 >;         /* in zephyr/dts/arm/st/h7rs/stm32h7rs.dtsi:602 */
			status = "disabled";            /* in zephyr/dts/arm/st/h7rs/stm32h7rs.dtsi:603 */

			/* node '/soc/timers@40000000/pwm' defined in zephyr/dts/arm/st/h7rs/stm32h7rs.dtsi:605 */
			pwm {
				compatible = "st,stm32-pwm"; /* in zephyr/dts/arm/st/h7rs/stm32h7rs.dtsi:606 */
				status = "disabled";         /* in zephyr/dts/arm/st/h7rs/stm32h7rs.dtsi:607 */
				#pwm-cells = < 0x3 >;        /* in zephyr/dts/arm/st/h7rs/stm32h7rs.dtsi:608 */
			};

			/* node '/soc/timers@40000000/counter' defined in zephyr/dts/arm/st/h7rs/stm32h7rs.dtsi:611 */
			counter {
				compatible = "st,stm32-counter"; /* in zephyr/dts/arm/st/h7rs/stm32h7rs.dtsi:612 */
				status = "disabled";             /* in zephyr/dts/arm/st/h7rs/stm32h7rs.dtsi:613 */
			};
		};

		/* node '/soc/timers@40000400' defined in zephyr/dts/arm/st/h7rs/stm32h7rs.dtsi:617 */
		timers3: timers@40000400 {
			compatible = "st,stm32-timers"; /* in zephyr/dts/arm/st/h7rs/stm32h7rs.dtsi:618 */
			reg = < 0x40000400 0x400 >;     /* in zephyr/dts/arm/st/h7rs/stm32h7rs.dtsi:619 */
			clocks = < &rcc 0x148 0x2 >,
			         < &rcc 0x1b 0xff >;    /* in zephyr/dts/arm/st/h7rs/stm32h7rs.dtsi:620 */
			resets = < &rctl 0x1201 >;      /* in zephyr/dts/arm/st/h7rs/stm32h7rs.dtsi:622 */
			interrupts = < 0x34 0x0 >;      /* in zephyr/dts/arm/st/h7rs/stm32h7rs.dtsi:623 */
			interrupt-names = "global";     /* in zephyr/dts/arm/st/h7rs/stm32h7rs.dtsi:624 */
			st,prescaler = < 0x0 >;         /* in zephyr/dts/arm/st/h7rs/stm32h7rs.dtsi:625 */
			status = "disabled";            /* in zephyr/dts/arm/st/h7rs/stm32h7rs.dtsi:626 */

			/* node '/soc/timers@40000400/pwm' defined in zephyr/dts/arm/st/h7rs/stm32h7rs.dtsi:628 */
			pwm {
				compatible = "st,stm32-pwm"; /* in zephyr/dts/arm/st/h7rs/stm32h7rs.dtsi:629 */
				status = "disabled";         /* in zephyr/dts/arm/st/h7rs/stm32h7rs.dtsi:630 */
				#pwm-cells = < 0x3 >;        /* in zephyr/dts/arm/st/h7rs/stm32h7rs.dtsi:631 */
			};

			/* node '/soc/timers@40000400/counter' defined in zephyr/dts/arm/st/h7rs/stm32h7rs.dtsi:634 */
			counter {
				compatible = "st,stm32-counter"; /* in zephyr/dts/arm/st/h7rs/stm32h7rs.dtsi:635 */
				status = "disabled";             /* in zephyr/dts/arm/st/h7rs/stm32h7rs.dtsi:636 */
			};
		};

		/* node '/soc/timers@40000800' defined in zephyr/dts/arm/st/h7rs/stm32h7rs.dtsi:640 */
		timers4: timers@40000800 {
			compatible = "st,stm32-timers"; /* in zephyr/dts/arm/st/h7rs/stm32h7rs.dtsi:641 */
			reg = < 0x40000800 0x400 >;     /* in zephyr/dts/arm/st/h7rs/stm32h7rs.dtsi:642 */
			clocks = < &rcc 0x148 0x4 >,
			         < &rcc 0x1b 0xff >;    /* in zephyr/dts/arm/st/h7rs/stm32h7rs.dtsi:643 */
			resets = < &rctl 0x1202 >;      /* in zephyr/dts/arm/st/h7rs/stm32h7rs.dtsi:645 */
			interrupts = < 0x35 0x0 >;      /* in zephyr/dts/arm/st/h7rs/stm32h7rs.dtsi:646 */
			interrupt-names = "global";     /* in zephyr/dts/arm/st/h7rs/stm32h7rs.dtsi:647 */
			st,prescaler = < 0x0 >;         /* in zephyr/dts/arm/st/h7rs/stm32h7rs.dtsi:648 */
			status = "disabled";            /* in zephyr/dts/arm/st/h7rs/stm32h7rs.dtsi:649 */

			/* node '/soc/timers@40000800/pwm' defined in zephyr/dts/arm/st/h7rs/stm32h7rs.dtsi:651 */
			pwm {
				compatible = "st,stm32-pwm"; /* in zephyr/dts/arm/st/h7rs/stm32h7rs.dtsi:652 */
				status = "disabled";         /* in zephyr/dts/arm/st/h7rs/stm32h7rs.dtsi:653 */
				#pwm-cells = < 0x3 >;        /* in zephyr/dts/arm/st/h7rs/stm32h7rs.dtsi:654 */
			};

			/* node '/soc/timers@40000800/counter' defined in zephyr/dts/arm/st/h7rs/stm32h7rs.dtsi:657 */
			counter {
				compatible = "st,stm32-counter"; /* in zephyr/dts/arm/st/h7rs/stm32h7rs.dtsi:658 */
				status = "disabled";             /* in zephyr/dts/arm/st/h7rs/stm32h7rs.dtsi:659 */
			};
		};

		/* node '/soc/timers@40000c00' defined in zephyr/dts/arm/st/h7rs/stm32h7rs.dtsi:663 */
		timers5: timers@40000c00 {
			compatible = "st,stm32-timers"; /* in zephyr/dts/arm/st/h7rs/stm32h7rs.dtsi:664 */
			reg = < 0x40000c00 0x400 >;     /* in zephyr/dts/arm/st/h7rs/stm32h7rs.dtsi:665 */
			clocks = < &rcc 0x148 0x8 >,
			         < &rcc 0x1b 0xff >;    /* in zephyr/dts/arm/st/h7rs/stm32h7rs.dtsi:666 */
			resets = < &rctl 0x1203 >;      /* in zephyr/dts/arm/st/h7rs/stm32h7rs.dtsi:668 */
			interrupts = < 0x36 0x0 >;      /* in zephyr/dts/arm/st/h7rs/stm32h7rs.dtsi:669 */
			interrupt-names = "global";     /* in zephyr/dts/arm/st/h7rs/stm32h7rs.dtsi:670 */
			st,prescaler = < 0x0 >;         /* in zephyr/dts/arm/st/h7rs/stm32h7rs.dtsi:671 */
			status = "disabled";            /* in zephyr/dts/arm/st/h7rs/stm32h7rs.dtsi:672 */

			/* node '/soc/timers@40000c00/pwm' defined in zephyr/dts/arm/st/h7rs/stm32h7rs.dtsi:674 */
			pwm {
				compatible = "st,stm32-pwm"; /* in zephyr/dts/arm/st/h7rs/stm32h7rs.dtsi:675 */
				status = "disabled";         /* in zephyr/dts/arm/st/h7rs/stm32h7rs.dtsi:676 */
				#pwm-cells = < 0x3 >;        /* in zephyr/dts/arm/st/h7rs/stm32h7rs.dtsi:677 */
			};

			/* node '/soc/timers@40000c00/counter' defined in zephyr/dts/arm/st/h7rs/stm32h7rs.dtsi:680 */
			counter {
				compatible = "st,stm32-counter"; /* in zephyr/dts/arm/st/h7rs/stm32h7rs.dtsi:681 */
				status = "disabled";             /* in zephyr/dts/arm/st/h7rs/stm32h7rs.dtsi:682 */
			};
		};

		/* node '/soc/timers@40001000' defined in zephyr/dts/arm/st/h7rs/stm32h7rs.dtsi:686 */
		timers6: timers@40001000 {
			compatible = "st,stm32-timers"; /* in zephyr/dts/arm/st/h7rs/stm32h7rs.dtsi:687 */
			reg = < 0x40001000 0x400 >;     /* in zephyr/dts/arm/st/h7rs/stm32h7rs.dtsi:688 */
			clocks = < &rcc 0x148 0x10 >,
			         < &rcc 0x1b 0xff >;    /* in zephyr/dts/arm/st/h7rs/stm32h7rs.dtsi:689 */
			resets = < &rctl 0x1204 >;      /* in zephyr/dts/arm/st/h7rs/stm32h7rs.dtsi:691 */
			interrupts = < 0x37 0x0 >;      /* in zephyr/dts/arm/st/h7rs/stm32h7rs.dtsi:692 */
			interrupt-names = "global";     /* in zephyr/dts/arm/st/h7rs/stm32h7rs.dtsi:693 */
			st,prescaler = < 0x0 >;         /* in zephyr/dts/arm/st/h7rs/stm32h7rs.dtsi:694 */
			status = "disabled";            /* in zephyr/dts/arm/st/h7rs/stm32h7rs.dtsi:695 */

			/* node '/soc/timers@40001000/counter' defined in zephyr/dts/arm/st/h7rs/stm32h7rs.dtsi:697 */
			counter {
				compatible = "st,stm32-counter"; /* in zephyr/dts/arm/st/h7rs/stm32h7rs.dtsi:698 */
				status = "disabled";             /* in zephyr/dts/arm/st/h7rs/stm32h7rs.dtsi:699 */
			};
		};

		/* node '/soc/timers@40001400' defined in zephyr/dts/arm/st/h7rs/stm32h7rs.dtsi:703 */
		timers7: timers@40001400 {
			compatible = "st,stm32-timers"; /* in zephyr/dts/arm/st/h7rs/stm32h7rs.dtsi:704 */
			reg = < 0x40001400 0x400 >;     /* in zephyr/dts/arm/st/h7rs/stm32h7rs.dtsi:705 */
			clocks = < &rcc 0x148 0x20 >,
			         < &rcc 0x1b 0xff >;    /* in zephyr/dts/arm/st/h7rs/stm32h7rs.dtsi:706 */
			resets = < &rctl 0x1205 >;      /* in zephyr/dts/arm/st/h7rs/stm32h7rs.dtsi:708 */
			interrupts = < 0x38 0x0 >;      /* in zephyr/dts/arm/st/h7rs/stm32h7rs.dtsi:709 */
			interrupt-names = "global";     /* in zephyr/dts/arm/st/h7rs/stm32h7rs.dtsi:710 */
			st,prescaler = < 0x0 >;         /* in zephyr/dts/arm/st/h7rs/stm32h7rs.dtsi:711 */
			status = "disabled";            /* in zephyr/dts/arm/st/h7rs/stm32h7rs.dtsi:712 */

			/* node '/soc/timers@40001400/counter' defined in zephyr/dts/arm/st/h7rs/stm32h7rs.dtsi:714 */
			counter {
				compatible = "st,stm32-counter"; /* in zephyr/dts/arm/st/h7rs/stm32h7rs.dtsi:715 */
				status = "disabled";             /* in zephyr/dts/arm/st/h7rs/stm32h7rs.dtsi:716 */
			};
		};

		/* node '/soc/timers@42004c00' defined in zephyr/dts/arm/st/h7rs/stm32h7rs.dtsi:720 */
		timers9: timers@42004c00 {
			compatible = "st,stm32-timers";  /* in zephyr/dts/arm/st/h7rs/stm32h7rs.dtsi:721 */
			reg = < 0x42004c00 0x400 >;      /* in zephyr/dts/arm/st/h7rs/stm32h7rs.dtsi:722 */
			clocks = < &rcc 0x150 0x80000 >,
			         < &rcc 0x1c 0xff >;     /* in zephyr/dts/arm/st/h7rs/stm32h7rs.dtsi:723 */
			resets = < &rctl 0x1313 >;       /* in zephyr/dts/arm/st/h7rs/stm32h7rs.dtsi:725 */
			interrupts = < 0x39 0x0 >;       /* in zephyr/dts/arm/st/h7rs/stm32h7rs.dtsi:726 */
			interrupt-names = "global";      /* in zephyr/dts/arm/st/h7rs/stm32h7rs.dtsi:727 */
			st,prescaler = < 0x0 >;          /* in zephyr/dts/arm/st/h7rs/stm32h7rs.dtsi:728 */
			status = "disabled";             /* in zephyr/dts/arm/st/h7rs/stm32h7rs.dtsi:729 */

			/* node '/soc/timers@42004c00/counter' defined in zephyr/dts/arm/st/h7rs/stm32h7rs.dtsi:731 */
			counter {
				compatible = "st,stm32-counter"; /* in zephyr/dts/arm/st/h7rs/stm32h7rs.dtsi:732 */
				status = "disabled";             /* in zephyr/dts/arm/st/h7rs/stm32h7rs.dtsi:733 */
			};
		};

		/* node '/soc/timers@42004000' defined in zephyr/dts/arm/st/h7rs/stm32h7rs.dtsi:737 */
		timers15: timers@42004000 {
			compatible = "st,stm32-timers";  /* in zephyr/dts/arm/st/h7rs/stm32h7rs.dtsi:738 */
			reg = < 0x42004000 0x400 >;      /* in zephyr/dts/arm/st/h7rs/stm32h7rs.dtsi:739 */
			clocks = < &rcc 0x150 0x10000 >,
			         < &rcc 0x1c 0xff >;     /* in zephyr/dts/arm/st/h7rs/stm32h7rs.dtsi:740 */
			resets = < &rctl 0x1310 >;       /* in zephyr/dts/arm/st/h7rs/stm32h7rs.dtsi:742 */
			interrupts = < 0x74 0x0 >;       /* in zephyr/dts/arm/st/h7rs/stm32h7rs.dtsi:743 */
			interrupt-names = "global";      /* in zephyr/dts/arm/st/h7rs/stm32h7rs.dtsi:744 */
			st,prescaler = < 0x0 >;          /* in zephyr/dts/arm/st/h7rs/stm32h7rs.dtsi:745 */
			status = "disabled";             /* in zephyr/dts/arm/st/h7rs/stm32h7rs.dtsi:746 */

			/* node '/soc/timers@42004000/pwm' defined in zephyr/dts/arm/st/h7rs/stm32h7rs.dtsi:748 */
			pwm {
				compatible = "st,stm32-pwm"; /* in zephyr/dts/arm/st/h7rs/stm32h7rs.dtsi:749 */
				status = "disabled";         /* in zephyr/dts/arm/st/h7rs/stm32h7rs.dtsi:750 */
				#pwm-cells = < 0x3 >;        /* in zephyr/dts/arm/st/h7rs/stm32h7rs.dtsi:751 */
			};

			/* node '/soc/timers@42004000/counter' defined in zephyr/dts/arm/st/h7rs/stm32h7rs.dtsi:754 */
			counter {
				compatible = "st,stm32-counter"; /* in zephyr/dts/arm/st/h7rs/stm32h7rs.dtsi:755 */
				status = "disabled";             /* in zephyr/dts/arm/st/h7rs/stm32h7rs.dtsi:756 */
			};
		};

		/* node '/soc/timers@42004400' defined in zephyr/dts/arm/st/h7rs/stm32h7rs.dtsi:760 */
		timers16: timers@42004400 {
			compatible = "st,stm32-timers";  /* in zephyr/dts/arm/st/h7rs/stm32h7rs.dtsi:761 */
			reg = < 0x42004400 0x400 >;      /* in zephyr/dts/arm/st/h7rs/stm32h7rs.dtsi:762 */
			clocks = < &rcc 0x150 0x20000 >,
			         < &rcc 0x1c 0xff >;     /* in zephyr/dts/arm/st/h7rs/stm32h7rs.dtsi:763 */
			resets = < &rctl 0x1311 >;       /* in zephyr/dts/arm/st/h7rs/stm32h7rs.dtsi:765 */
			interrupts = < 0x75 0x0 >;       /* in zephyr/dts/arm/st/h7rs/stm32h7rs.dtsi:766 */
			interrupt-names = "global";      /* in zephyr/dts/arm/st/h7rs/stm32h7rs.dtsi:767 */
			st,prescaler = < 0x0 >;          /* in zephyr/dts/arm/st/h7rs/stm32h7rs.dtsi:768 */
			status = "disabled";             /* in zephyr/dts/arm/st/h7rs/stm32h7rs.dtsi:769 */

			/* node '/soc/timers@42004400/pwm' defined in zephyr/dts/arm/st/h7rs/stm32h7rs.dtsi:771 */
			pwm {
				compatible = "st,stm32-pwm"; /* in zephyr/dts/arm/st/h7rs/stm32h7rs.dtsi:772 */
				status = "disabled";         /* in zephyr/dts/arm/st/h7rs/stm32h7rs.dtsi:773 */
				#pwm-cells = < 0x3 >;        /* in zephyr/dts/arm/st/h7rs/stm32h7rs.dtsi:774 */
			};

			/* node '/soc/timers@42004400/counter' defined in zephyr/dts/arm/st/h7rs/stm32h7rs.dtsi:777 */
			counter {
				compatible = "st,stm32-counter"; /* in zephyr/dts/arm/st/h7rs/stm32h7rs.dtsi:778 */
				status = "disabled";             /* in zephyr/dts/arm/st/h7rs/stm32h7rs.dtsi:779 */
			};
		};

		/* node '/soc/timers@42004800' defined in zephyr/dts/arm/st/h7rs/stm32h7rs.dtsi:783 */
		timers17: timers@42004800 {
			compatible = "st,stm32-timers";  /* in zephyr/dts/arm/st/h7rs/stm32h7rs.dtsi:784 */
			reg = < 0x42004800 0x400 >;      /* in zephyr/dts/arm/st/h7rs/stm32h7rs.dtsi:785 */
			clocks = < &rcc 0x150 0x40000 >,
			         < &rcc 0x1c 0xff >;     /* in zephyr/dts/arm/st/h7rs/stm32h7rs.dtsi:786 */
			resets = < &rctl 0x1312 >;       /* in zephyr/dts/arm/st/h7rs/stm32h7rs.dtsi:788 */
			interrupts = < 0x76 0x0 >;       /* in zephyr/dts/arm/st/h7rs/stm32h7rs.dtsi:789 */
			interrupt-names = "global";      /* in zephyr/dts/arm/st/h7rs/stm32h7rs.dtsi:790 */
			st,prescaler = < 0x0 >;          /* in zephyr/dts/arm/st/h7rs/stm32h7rs.dtsi:791 */
			status = "disabled";             /* in zephyr/dts/arm/st/h7rs/stm32h7rs.dtsi:792 */

			/* node '/soc/timers@42004800/pwm' defined in zephyr/dts/arm/st/h7rs/stm32h7rs.dtsi:794 */
			pwm {
				compatible = "st,stm32-pwm"; /* in zephyr/dts/arm/st/h7rs/stm32h7rs.dtsi:795 */
				status = "disabled";         /* in zephyr/dts/arm/st/h7rs/stm32h7rs.dtsi:796 */
				#pwm-cells = < 0x3 >;        /* in zephyr/dts/arm/st/h7rs/stm32h7rs.dtsi:797 */
			};

			/* node '/soc/timers@42004800/counter' defined in zephyr/dts/arm/st/h7rs/stm32h7rs.dtsi:800 */
			counter {
				compatible = "st,stm32-counter"; /* in zephyr/dts/arm/st/h7rs/stm32h7rs.dtsi:801 */
				status = "disabled";             /* in zephyr/dts/arm/st/h7rs/stm32h7rs.dtsi:802 */
			};
		};

		/* node '/soc/timers@40002400' defined in zephyr/dts/arm/st/h7rs/stm32h7rs.dtsi:806 */
		lptim1: timers@40002400 {
			compatible = "st,stm32-lptim"; /* in zephyr/dts/arm/st/h7rs/stm32h7rs.dtsi:807 */
			clocks = < &rcc 0x148 0x200 >; /* in zephyr/dts/arm/st/h7rs/stm32h7rs.dtsi:808 */
			#address-cells = < 0x1 >;      /* in zephyr/dts/arm/st/h7rs/stm32h7rs.dtsi:809 */
			#size-cells = < 0x0 >;         /* in zephyr/dts/arm/st/h7rs/stm32h7rs.dtsi:810 */
			reg = < 0x40002400 0x400 >;    /* in zephyr/dts/arm/st/h7rs/stm32h7rs.dtsi:811 */
			interrupts = < 0x77 0x1 >;     /* in zephyr/dts/arm/st/h7rs/stm32h7rs.dtsi:812 */
			interrupt-names = "wakeup";    /* in zephyr/dts/arm/st/h7rs/stm32h7rs.dtsi:813 */
			status = "disabled";           /* in zephyr/dts/arm/st/h7rs/stm32h7rs.dtsi:814 */
		};

		/* node '/soc/adc@40022000' defined in zephyr/dts/arm/st/h7rs/stm32h7rs.dtsi:817 */
		adc1: adc@40022000 {
			compatible = "st,stm32-adc";                                /* in zephyr/dts/arm/st/h7rs/stm32h7rs.dtsi:818 */
			reg = < 0x40022000 0x400 >;                                 /* in zephyr/dts/arm/st/h7rs/stm32h7rs.dtsi:819 */
			clocks = < &rcc 0x138 0x20 >;                               /* in zephyr/dts/arm/st/h7rs/stm32h7rs.dtsi:820 */
			clock-names = "adcx";                                       /* in zephyr/dts/arm/st/h7rs/stm32h7rs.dtsi:821 */
			interrupts = < 0x26 0x0 >;                                  /* in zephyr/dts/arm/st/h7rs/stm32h7rs.dtsi:822 */
			#io-channel-cells = < 0x1 >;                                /* in zephyr/dts/arm/st/h7rs/stm32h7rs.dtsi:823 */
			resolutions = < 0x60e20c 0x51e20c 0x42e20c 0x33e20c >;      /* in zephyr/dts/arm/st/h7rs/stm32h7rs.dtsi:824 */
			sampling-times = < 0x3 0x7 0xd 0x19 0x30 0x5d 0xf8 0x281 >; /* in zephyr/dts/arm/st/h7rs/stm32h7rs.dtsi:828 */
			st,adc-sequencer = "programmable";                          /* in zephyr/dts/arm/st/h7rs/stm32h7rs.dtsi:829 */
			st,adc-oversampler = "minimal";                             /* in zephyr/dts/arm/st/h7rs/stm32h7rs.dtsi:830 */
			st,adc-internal-regulator = "startup-sw-delay";             /* in zephyr/dts/arm/st/h7rs/stm32h7rs.dtsi:831 */
			st,adc-has-deep-powerdown;                                  /* in zephyr/dts/arm/st/h7rs/stm32h7rs.dtsi:832 */
			st,adc-has-differential-support;                            /* in zephyr/dts/arm/st/h7rs/stm32h7rs.dtsi:833 */
			status = "disabled";                                        /* in zephyr/dts/arm/st/h7rs/stm32h7rs.dtsi:834 */
			phandle = < 0xa >;                                          /* in zephyr/dts/arm/st/h7rs/stm32h7rs.dtsi:964 */
		};

		/* node '/soc/adc@40022100' defined in zephyr/dts/arm/st/h7rs/stm32h7rs.dtsi:837 */
		adc2: adc@40022100 {
			compatible = "st,stm32-adc";                                /* in zephyr/dts/arm/st/h7rs/stm32h7rs.dtsi:838 */
			reg = < 0x40022100 0x400 >;                                 /* in zephyr/dts/arm/st/h7rs/stm32h7rs.dtsi:839 */
			clocks = < &rcc 0x138 0x20 >;                               /* in zephyr/dts/arm/st/h7rs/stm32h7rs.dtsi:840 */
			clock-names = "adcx";                                       /* in zephyr/dts/arm/st/h7rs/stm32h7rs.dtsi:841 */
			interrupts = < 0x26 0x0 >;                                  /* in zephyr/dts/arm/st/h7rs/stm32h7rs.dtsi:842 */
			#io-channel-cells = < 0x1 >;                                /* in zephyr/dts/arm/st/h7rs/stm32h7rs.dtsi:843 */
			resolutions = < 0x60e20c 0x51e20c 0x42e20c 0x33e20c >;      /* in zephyr/dts/arm/st/h7rs/stm32h7rs.dtsi:844 */
			sampling-times = < 0x3 0x7 0xd 0x19 0x30 0x5d 0xf8 0x281 >; /* in zephyr/dts/arm/st/h7rs/stm32h7rs.dtsi:848 */
			st,adc-sequencer = "programmable";                          /* in zephyr/dts/arm/st/h7rs/stm32h7rs.dtsi:849 */
			st,adc-oversampler = "minimal";                             /* in zephyr/dts/arm/st/h7rs/stm32h7rs.dtsi:850 */
			st,adc-internal-regulator = "startup-sw-delay";             /* in zephyr/dts/arm/st/h7rs/stm32h7rs.dtsi:851 */
			st,adc-has-deep-powerdown;                                  /* in zephyr/dts/arm/st/h7rs/stm32h7rs.dtsi:852 */
			st,adc-has-differential-support;                            /* in zephyr/dts/arm/st/h7rs/stm32h7rs.dtsi:853 */
			status = "disabled";                                        /* in zephyr/dts/arm/st/h7rs/stm32h7rs.dtsi:854 */
			phandle = < 0xb >;                                          /* in zephyr/dts/arm/st/h7rs/stm32h7rs.dtsi:972 */
		};

		/* node '/soc/rng@48020000' defined in zephyr/dts/arm/st/h7rs/stm32h7rs.dtsi:857 */
		rng: rng@48020000 {
			compatible = "st,stm32-rng"; /* in zephyr/dts/arm/st/h7rs/stm32h7rs.dtsi:858 */
			reg = < 0x48020000 0x400 >;  /* in zephyr/dts/arm/st/h7rs/stm32h7rs.dtsi:859 */
			clocks = < &rcc 0x158 0x1 >; /* in zephyr/dts/arm/st/h7rs/stm32h7rs.dtsi:860 */
			interrupts = < 0x25 0x0 >;   /* in zephyr/dts/arm/st/h7rs/stm32h7rs.dtsi:861 */
			status = "okay";             /* in zephyr/boards/ruiside/art_pi2/art_pi2.dts:102 */
		};

		/* node '/soc/ethernet@40028000' defined in zephyr/dts/arm/st/h7rs/stm32h7rs.dtsi:865 */
		ethernet@40028000 {
			reg = < 0x40028000 0x8000 >;                 /* in zephyr/dts/arm/st/h7rs/stm32h7rs.dtsi:866 */
			compatible = "st,stm32-ethernet-controller"; /* in zephyr/dts/arm/st/h7rs/stm32h7rs.dtsi:867 */
			clock-names = "stm-eth";                     /* in zephyr/dts/arm/st/h7rs/stm32h7rs.dtsi:868 */
			clocks = < &rcc 0x138 0x8000 >;              /* in zephyr/dts/arm/st/h7rs/stm32h7rs.dtsi:869 */

			/* node '/soc/ethernet@40028000/ethernet' defined in zephyr/dts/arm/st/h7rs/stm32h7rs.dtsi:871 */
			mac: ethernet {
				compatible = "st,stm32h7-ethernet",
				             "st,stm32-ethernet";   /* in zephyr/dts/arm/st/h7rs/stm32h7rs.dtsi:872 */
				interrupts = < 0x5c 0x0 >;          /* in zephyr/dts/arm/st/h7rs/stm32h7rs.dtsi:873 */
				clock-names = "mac-clk-tx",
				              "mac-clk-rx";         /* in zephyr/dts/arm/st/h7rs/stm32h7rs.dtsi:874 */
				clocks = < &rcc 0x138 0x10000 >,
				         < &rcc 0x138 0x20000 >;    /* in zephyr/dts/arm/st/h7rs/stm32h7rs.dtsi:875 */
				status = "disabled";                /* in zephyr/dts/arm/st/h7rs/stm32h7rs.dtsi:877 */
			};

			/* node '/soc/ethernet@40028000/mdio' defined in zephyr/dts/arm/st/h7rs/stm32h7rs.dtsi:880 */
			mdio: mdio {
				compatible = "st,stm32-mdio"; /* in zephyr/dts/arm/st/h7rs/stm32h7rs.dtsi:881 */
				#address-cells = < 0x1 >;     /* in zephyr/dts/arm/st/h7rs/stm32h7rs.dtsi:882 */
				#size-cells = < 0x0 >;        /* in zephyr/dts/arm/st/h7rs/stm32h7rs.dtsi:883 */
				status = "disabled";          /* in zephyr/dts/arm/st/h7rs/stm32h7rs.dtsi:884 */
			};
		};

		/* node '/soc/usb@40080000' defined in zephyr/dts/arm/st/h7rs/stm32h7rs.dtsi:888 */
		usbotg_fs: usb@40080000 {
			compatible = "st,stm32-otgfs";     /* in zephyr/dts/arm/st/h7rs/stm32h7rs.dtsi:889 */
			reg = < 0x40080000 0x40000 >;      /* in zephyr/dts/arm/st/h7rs/stm32h7rs.dtsi:890 */
			interrupts = < 0x70 0x0 >;         /* in zephyr/dts/arm/st/h7rs/stm32h7rs.dtsi:891 */
			interrupt-names = "otgfs";         /* in zephyr/dts/arm/st/h7rs/stm32h7rs.dtsi:892 */
			num-bidir-endpoints = < 0x6 >;     /* in zephyr/dts/arm/st/h7rs/stm32h7rs.dtsi:893 */
			ram-size = < 0x500 >;              /* in zephyr/dts/arm/st/h7rs/stm32h7rs.dtsi:894 */
			maximum-speed = "full-speed";      /* in zephyr/dts/arm/st/h7rs/stm32h7rs.dtsi:895 */
			phys = < &otgfs_phy >;             /* in zephyr/dts/arm/st/h7rs/stm32h7rs.dtsi:896 */
			clocks = < &rcc 0x138 0x8000000 >,
			         < &rcc 0x5 0x2e004c >;    /* in zephyr/dts/arm/st/h7rs/stm32h7rs.dtsi:897 */
			status = "disabled";               /* in zephyr/dts/arm/st/h7rs/stm32h7rs.dtsi:899 */
		};

		/* node '/soc/dma@40021000' defined in zephyr/dts/arm/st/h7rs/stm32h7rs.dtsi:902 */
		gpdma1: dma@40021000 {
			compatible = "st,stm32u5-dma";                                                                  /* in zephyr/dts/arm/st/h7rs/stm32h7rs.dtsi:903 */
			#dma-cells = < 0x3 >;                                                                           /* in zephyr/dts/arm/st/h7rs/stm32h7rs.dtsi:904 */
			reg = < 0x40021000 0x1000 >;                                                                    /* in zephyr/dts/arm/st/h7rs/stm32h7rs.dtsi:905 */
			clocks = < &rcc 0x138 0x10 >;                                                                   /* in zephyr/dts/arm/st/h7rs/stm32h7rs.dtsi:906 */
			interrupts = < 0x27 0x0 0x28 0x0 0x29 0x0 0x2a 0x0 0x2b 0x0 0x2c 0x0 0x2d 0x0 0x2e 0x0 0x85 0x0
			               0x86 0x0 0x87 0x0 0x88 0x0 0x89 0x0 0x8a 0x0 0x8b 0x0 0x8c 0x0 >;                /* in zephyr/dts/arm/st/h7rs/stm32h7rs.dtsi:907 */
			dma-channels = < 0x10 >;                                                                        /* in zephyr/dts/arm/st/h7rs/stm32h7rs.dtsi:909 */
			dma-requests = < 0x6d >;                                                                        /* in zephyr/dts/arm/st/h7rs/stm32h7rs.dtsi:910 */
			dma-offset = < 0x0 >;                                                                           /* in zephyr/dts/arm/st/h7rs/stm32h7rs.dtsi:911 */
			status = "disabled";                                                                            /* in zephyr/dts/arm/st/h7rs/stm32h7rs.dtsi:912 */
			phandle = < 0x8 >;                                                                              /* in zephyr/dts/arm/st/h7rs/stm32h7rs.dtsi:922 */
		};

		/* node '/soc/sai1@42005804' defined in zephyr/dts/arm/st/h7rs/stm32h7rs.dtsi:915 */
		sai1_a: sai1@42005804 {
			compatible = "st,stm32-sai";         /* in zephyr/dts/arm/st/h7rs/stm32h7rs.dtsi:916 */
			#address-cells = < 0x1 >;            /* in zephyr/dts/arm/st/h7rs/stm32h7rs.dtsi:917 */
			#size-cells = < 0x0 >;               /* in zephyr/dts/arm/st/h7rs/stm32h7rs.dtsi:918 */
			reg = < 0x42005804 0x20 >;           /* in zephyr/dts/arm/st/h7rs/stm32h7rs.dtsi:919 */
			clocks = < &rcc 0x150 0x400000 >,
			         < &rcc 0x11 0x2500054 >;    /* in zephyr/dts/arm/st/h7rs/stm32h7rs.dtsi:920 */
			dmas = < &gpdma1 0x1 0x3f 0x22800 >; /* in zephyr/dts/arm/st/h7rs/stm32h7rs.dtsi:922 */
			status = "disabled";                 /* in zephyr/dts/arm/st/h7rs/stm32h7rs.dtsi:924 */
		};

		/* node '/soc/sai1@42005824' defined in zephyr/dts/arm/st/h7rs/stm32h7rs.dtsi:927 */
		sai1_b: sai1@42005824 {
			compatible = "st,stm32-sai";         /* in zephyr/dts/arm/st/h7rs/stm32h7rs.dtsi:928 */
			#address-cells = < 0x1 >;            /* in zephyr/dts/arm/st/h7rs/stm32h7rs.dtsi:929 */
			#size-cells = < 0x0 >;               /* in zephyr/dts/arm/st/h7rs/stm32h7rs.dtsi:930 */
			reg = < 0x42005824 0x20 >;           /* in zephyr/dts/arm/st/h7rs/stm32h7rs.dtsi:931 */
			clocks = < &rcc 0x150 0x400000 >,
			         < &rcc 0x11 0x2500054 >;    /* in zephyr/dts/arm/st/h7rs/stm32h7rs.dtsi:932 */
			dmas = < &gpdma1 0x0 0x40 0x22800 >; /* in zephyr/dts/arm/st/h7rs/stm32h7rs.dtsi:934 */
			status = "disabled";                 /* in zephyr/dts/arm/st/h7rs/stm32h7rs.dtsi:936 */
		};

		/* node '/soc/ltdc@50001000' defined in zephyr/dts/arm/st/h7rs/stm32h7rs.dtsi:939 */
		ltdc: ltdc@50001000 {
			compatible = "st,stm32-ltdc"; /* in zephyr/dts/arm/st/h7rs/stm32h7rs.dtsi:940 */
			reg = < 0x50001000 0x400 >;   /* in zephyr/dts/arm/st/h7rs/stm32h7rs.dtsi:941 */
			interrupts = < 0x60 0x0 >,
			             < 0x61 0x0 >;    /* in zephyr/dts/arm/st/h7rs/stm32h7rs.dtsi:942 */
			interrupt-names = "ltdc",
			                  "ltdc_er";  /* in zephyr/dts/arm/st/h7rs/stm32h7rs.dtsi:943 */
			clocks = < &rcc 0x144 0x2 >,
			         < &rcc 0x13 0xff >;  /* in zephyr/dts/arm/st/h7rs/stm32h7rs.dtsi:944 */
			resets = < &rctl 0x1181 >;    /* in zephyr/dts/arm/st/h7rs/stm32h7rs.dtsi:946 */
			status = "disabled";          /* in zephyr/dts/arm/st/h7rs/stm32h7rs.dtsi:947 */
		};
	};

	/* node '/cpus' defined in zephyr/dts/arm/st/h7rs/stm32h7rs.dtsi:34 */
	cpus {
		#address-cells = < 0x1 >; /* in zephyr/dts/arm/st/h7rs/stm32h7rs.dtsi:35 */
		#size-cells = < 0x0 >;    /* in zephyr/dts/arm/st/h7rs/stm32h7rs.dtsi:36 */

		/* node '/cpus/cpu@0' defined in zephyr/dts/arm/st/h7rs/stm32h7rs.dtsi:38 */
		cpu0: cpu@0 {
			device_type = "cpu";          /* in zephyr/dts/arm/st/h7rs/stm32h7rs.dtsi:39 */
			compatible = "arm,cortex-m7"; /* in zephyr/dts/arm/st/h7rs/stm32h7rs.dtsi:40 */
			reg = < 0x0 >;                /* in zephyr/dts/arm/st/h7rs/stm32h7rs.dtsi:41 */
			#address-cells = < 0x1 >;     /* in zephyr/dts/arm/st/h7rs/stm32h7rs.dtsi:42 */
			#size-cells = < 0x1 >;        /* in zephyr/dts/arm/st/h7rs/stm32h7rs.dtsi:43 */

			/* node '/cpus/cpu@0/mpu@e000ed90' defined in zephyr/dts/arm/st/h7rs/stm32h7rs.dtsi:45 */
			mpu: mpu@e000ed90 {
				compatible = "arm,armv7m-mpu"; /* in zephyr/dts/arm/st/h7rs/stm32h7rs.dtsi:46 */
				reg = < 0xe000ed90 0x40 >;     /* in zephyr/dts/arm/st/h7rs/stm32h7rs.dtsi:47 */
			};
		};
	};

	/* node '/memory@24000000' defined in zephyr/dts/arm/st/h7rs/stm32h7rs.dtsi:53 */
	sram0: memory@24000000 {
		reg = < 0x24000000 0x72000 >;        /* in zephyr/dts/arm/st/h7rs/stm32h7rs.dtsi:54 */
		compatible = "zephyr,memory-region",
		             "mmio-sram";            /* in zephyr/dts/arm/st/h7rs/stm32h7rs.dtsi:55 */
		zephyr,memory-region = "SRAM0";      /* in zephyr/dts/arm/st/h7rs/stm32h7rs.dtsi:56 */
	};

	/* node '/memory@30000000' defined in zephyr/dts/arm/st/h7rs/stm32h7rs.dtsi:60 */
	sram1: memory@30000000 {
		reg = < 0x30000000 0x4000 >;         /* in zephyr/dts/arm/st/h7rs/stm32h7rs.dtsi:61 */
		compatible = "zephyr,memory-region",
		             "mmio-sram";            /* in zephyr/dts/arm/st/h7rs/stm32h7rs.dtsi:62 */
		zephyr,memory-region = "SRAM1";      /* in zephyr/dts/arm/st/h7rs/stm32h7rs.dtsi:63 */
		zephyr,memory-attr = < 0x100000 >;   /* in zephyr/dts/arm/st/h7rs/stm32h7rs.dtsi:64 */
	};

	/* node '/memory@30004000' defined in zephyr/dts/arm/st/h7rs/stm32h7rs.dtsi:68 */
	sram2: memory@30004000 {
		compatible = "zephyr,memory-region",
		             "mmio-sram";            /* in zephyr/dts/arm/st/h7rs/stm32h7rs.dtsi:69 */
		reg = < 0x30004000 0x4000 >;         /* in zephyr/dts/arm/st/h7rs/stm32h7rs.dtsi:70 */
		zephyr,memory-region = "SRAM2";      /* in zephyr/dts/arm/st/h7rs/stm32h7rs.dtsi:71 */
		status = "disabled";                 /* in zephyr/dts/arm/st/h7rs/stm32h7rs.dtsi:76 */
	};

	/* node '/memory@20000000' defined in zephyr/dts/arm/st/h7rs/stm32h7rs.dtsi:79 */
	dtcm: memory@20000000 {
		compatible = "zephyr,memory-region",
		             "arm,dtcm";             /* in zephyr/dts/arm/st/h7rs/stm32h7rs.dtsi:80 */
		zephyr,memory-region = "DTCM";       /* in zephyr/dts/arm/st/h7rs/stm32h7rs.dtsi:82 */
		reg = < 0x20000000 0x10000 >;        /* in zephyr/boards/ruiside/art_pi2/art_pi2.dts:59 */
	};

	/* node '/memory@0' defined in zephyr/dts/arm/st/h7rs/stm32h7rs.dtsi:85 */
	itcm: memory@0 {
		compatible = "zephyr,memory-region",
		             "arm,itcm";             /* in zephyr/dts/arm/st/h7rs/stm32h7rs.dtsi:86 */
		reg = < 0x0 0x10000 >;               /* in zephyr/dts/arm/st/h7rs/stm32h7rs.dtsi:87 */
		zephyr,memory-region = "ITCM";       /* in zephyr/dts/arm/st/h7rs/stm32h7rs.dtsi:88 */
	};

	/* node '/memory@70000000' defined in zephyr/dts/arm/st/h7rs/stm32h7rs.dtsi:91 */
	ext_memory: memory@70000000 {
		compatible = "zephyr,memory-region"; /* in zephyr/dts/arm/st/h7rs/stm32h7rs.dtsi:92 */
		reg = < 0x70000000 0x10000000 >;     /* in zephyr/dts/arm/st/h7rs/stm32h7rs.dtsi:93 */
		zephyr,memory-region = "EXTMEM";     /* in zephyr/dts/arm/st/h7rs/stm32h7rs.dtsi:94 */
		zephyr,memory-attr = < 0x1000000 >;  /* in zephyr/dts/arm/st/h7rs/stm32h7rs.dtsi:96 */
	};

	/* node '/clocks' defined in zephyr/dts/arm/st/h7rs/stm32h7rs.dtsi:99 */
	clocks {
		#address-cells = < 0x1 >; /* in zephyr/dts/arm/st/h7rs/stm32h7rs.dtsi:100 */
		#size-cells = < 0x0 >;    /* in zephyr/dts/arm/st/h7rs/stm32h7rs.dtsi:101 */

		/* node '/clocks/clk-hse' defined in zephyr/dts/arm/st/h7rs/stm32h7rs.dtsi:103 */
		clk_hse: clk-hse {
			#clock-cells = < 0x0 >;            /* in zephyr/dts/arm/st/h7rs/stm32h7rs.dtsi:104 */
			compatible = "st,stm32-hse-clock"; /* in zephyr/dts/arm/st/h7rs/stm32h7rs.dtsi:105 */
			clock-frequency = < 0x16e3600 >;   /* in zephyr/boards/ruiside/art_pi2/art_pi2.dts:67 */
			status = "okay";                   /* in zephyr/boards/ruiside/art_pi2/art_pi2.dts:68 */
			phandle = < 0x9 >;                 /* in zephyr/boards/ruiside/art_pi2/art_pi2.dts:79 */
		};

		/* node '/clocks/clk-hsi' defined in zephyr/dts/arm/st/h7rs/stm32h7rs.dtsi:109 */
		clk_hsi: clk-hsi {
			#clock-cells = < 0x0 >;              /* in zephyr/dts/arm/st/h7rs/stm32h7rs.dtsi:110 */
			compatible = "st,stm32h7-hsi-clock"; /* in zephyr/dts/arm/st/h7rs/stm32h7rs.dtsi:111 */
			hsi-div = < 0x1 >;                   /* in zephyr/dts/arm/st/h7rs/stm32h7rs.dtsi:112 */
			clock-frequency = < 0x3d09000 >;     /* in zephyr/dts/arm/st/h7rs/stm32h7rs.dtsi:113 */
			status = "disabled";                 /* in zephyr/dts/arm/st/h7rs/stm32h7rs.dtsi:114 */
		};

		/* node '/clocks/clk-hsi48' defined in zephyr/dts/arm/st/h7rs/stm32h7rs.dtsi:117 */
		clk_hsi48: clk-hsi48 {
			#clock-cells = < 0x0 >;          /* in zephyr/dts/arm/st/h7rs/stm32h7rs.dtsi:118 */
			compatible = "fixed-clock";      /* in zephyr/dts/arm/st/h7rs/stm32h7rs.dtsi:119 */
			clock-frequency = < 0x2dc6c00 >; /* in zephyr/dts/arm/st/h7rs/stm32h7rs.dtsi:120 */
			status = "okay";                 /* in zephyr/boards/ruiside/art_pi2/art_pi2.dts:63 */
		};

		/* node '/clocks/clk-csi' defined in zephyr/dts/arm/st/h7rs/stm32h7rs.dtsi:124 */
		clk_csi: clk-csi {
			#clock-cells = < 0x0 >;         /* in zephyr/dts/arm/st/h7rs/stm32h7rs.dtsi:125 */
			compatible = "fixed-clock";     /* in zephyr/dts/arm/st/h7rs/stm32h7rs.dtsi:126 */
			clock-frequency = < 0x3d0900 >; /* in zephyr/dts/arm/st/h7rs/stm32h7rs.dtsi:127 */
			status = "disabled";            /* in zephyr/dts/arm/st/h7rs/stm32h7rs.dtsi:128 */
		};

		/* node '/clocks/clk-lse' defined in zephyr/dts/arm/st/h7rs/stm32h7rs.dtsi:131 */
		clk_lse: clk-lse {
			#clock-cells = < 0x0 >;            /* in zephyr/dts/arm/st/h7rs/stm32h7rs.dtsi:132 */
			compatible = "st,stm32-lse-clock"; /* in zephyr/dts/arm/st/h7rs/stm32h7rs.dtsi:133 */
			clock-frequency = < 0x8000 >;      /* in zephyr/dts/arm/st/h7rs/stm32h7rs.dtsi:134 */
			driving-capability = < 0x0 >;      /* in zephyr/dts/arm/st/h7rs/stm32h7rs.dtsi:135 */
			status = "disabled";               /* in zephyr/dts/arm/st/h7rs/stm32h7rs.dtsi:136 */
		};

		/* node '/clocks/clk-lsi' defined in zephyr/dts/arm/st/h7rs/stm32h7rs.dtsi:139 */
		clk_lsi: clk-lsi {
			#clock-cells = < 0x0 >;       /* in zephyr/dts/arm/st/h7rs/stm32h7rs.dtsi:140 */
			compatible = "fixed-clock";   /* in zephyr/dts/arm/st/h7rs/stm32h7rs.dtsi:141 */
			clock-frequency = < 0x7d00 >; /* in zephyr/dts/arm/st/h7rs/stm32h7rs.dtsi:142 */
			status = "disabled";          /* in zephyr/dts/arm/st/h7rs/stm32h7rs.dtsi:143 */
		};

		/* node '/clocks/pll@0' defined in zephyr/dts/arm/st/h7rs/stm32h7rs.dtsi:146 */
		pll: pll@0 {
			#clock-cells = < 0x0 >;                /* in zephyr/dts/arm/st/h7rs/stm32h7rs.dtsi:147 */
			compatible = "st,stm32h7rs-pll-clock"; /* in zephyr/dts/arm/st/h7rs/stm32h7rs.dtsi:148 */
			reg = < 0x0 >;                         /* in zephyr/dts/arm/st/h7rs/stm32h7rs.dtsi:149 */
			div-m = < 0xc >;                       /* in zephyr/boards/ruiside/art_pi2/art_pi2.dts:72 */
			mul-n = < 0xfa >;                      /* in zephyr/boards/ruiside/art_pi2/art_pi2.dts:73 */
			div-p = < 0x2 >;                       /* in zephyr/boards/ruiside/art_pi2/art_pi2.dts:74 */
			div-q = < 0x2 >;                       /* in zephyr/boards/ruiside/art_pi2/art_pi2.dts:75 */
			div-r = < 0x2 >;                       /* in zephyr/boards/ruiside/art_pi2/art_pi2.dts:76 */
			div-s = < 0x2 >;                       /* in zephyr/boards/ruiside/art_pi2/art_pi2.dts:77 */
			div-t = < 0x2 >;                       /* in zephyr/boards/ruiside/art_pi2/art_pi2.dts:78 */
			clocks = < &clk_hse >;                 /* in zephyr/boards/ruiside/art_pi2/art_pi2.dts:79 */
			status = "okay";                       /* in zephyr/boards/ruiside/art_pi2/art_pi2.dts:80 */
			phandle = < 0x2 >;                     /* in zephyr/boards/ruiside/art_pi2/art_pi2.dts:84 */
		};

		/* node '/clocks/pll@1' defined in zephyr/dts/arm/st/h7rs/stm32h7rs.dtsi:153 */
		pll2: pll@1 {
			#clock-cells = < 0x0 >;                /* in zephyr/dts/arm/st/h7rs/stm32h7rs.dtsi:154 */
			compatible = "st,stm32h7rs-pll-clock"; /* in zephyr/dts/arm/st/h7rs/stm32h7rs.dtsi:155 */
			reg = < 0x1 >;                         /* in zephyr/dts/arm/st/h7rs/stm32h7rs.dtsi:156 */
			status = "disabled";                   /* in zephyr/dts/arm/st/h7rs/stm32h7rs.dtsi:157 */
		};

		/* node '/clocks/pll@2' defined in zephyr/dts/arm/st/h7rs/stm32h7rs.dtsi:160 */
		pll3: pll@2 {
			#clock-cells = < 0x0 >;                /* in zephyr/dts/arm/st/h7rs/stm32h7rs.dtsi:161 */
			compatible = "st,stm32h7rs-pll-clock"; /* in zephyr/dts/arm/st/h7rs/stm32h7rs.dtsi:162 */
			reg = < 0x2 >;                         /* in zephyr/dts/arm/st/h7rs/stm32h7rs.dtsi:163 */
			status = "disabled";                   /* in zephyr/dts/arm/st/h7rs/stm32h7rs.dtsi:164 */
		};

		/* node '/clocks/perck' defined in zephyr/dts/arm/st/h7rs/stm32h7rs.dtsi:167 */
		perck: perck {
			#clock-cells = < 0x0 >;            /* in zephyr/dts/arm/st/h7rs/stm32h7rs.dtsi:168 */
			compatible = "st,stm32-clock-mux"; /* in zephyr/dts/arm/st/h7rs/stm32h7rs.dtsi:169 */
			status = "disabled";               /* in zephyr/dts/arm/st/h7rs/stm32h7rs.dtsi:170 */
		};
	};

	/* node '/mcos' defined in zephyr/dts/arm/st/h7rs/stm32h7rs.dtsi:174 */
	mcos {

		/* node '/mcos/mco1' defined in zephyr/dts/arm/st/h7rs/stm32h7rs.dtsi:175 */
		mco1: mco1 {
			compatible = "st,stm32-clock-mco"; /* in zephyr/dts/arm/st/h7rs/stm32h7rs.dtsi:176 */
			status = "disabled";               /* in zephyr/dts/arm/st/h7rs/stm32h7rs.dtsi:177 */
		};

		/* node '/mcos/mco2' defined in zephyr/dts/arm/st/h7rs/stm32h7rs.dtsi:180 */
		mco2: mco2 {
			compatible = "st,stm32-clock-mco"; /* in zephyr/dts/arm/st/h7rs/stm32h7rs.dtsi:181 */
			status = "disabled";               /* in zephyr/dts/arm/st/h7rs/stm32h7rs.dtsi:182 */
		};
	};

	/* node '/otgfs_phy' defined in zephyr/dts/arm/st/h7rs/stm32h7rs.dtsi:951 */
	otgfs_phy: otgfs_phy {
		compatible = "usb-nop-xceiv"; /* in zephyr/dts/arm/st/h7rs/stm32h7rs.dtsi:952 */
		#phy-cells = < 0x0 >;         /* in zephyr/dts/arm/st/h7rs/stm32h7rs.dtsi:953 */
		phandle = < 0x7 >;            /* in zephyr/dts/arm/st/h7rs/stm32h7rs.dtsi:896 */
	};

	/* node '/dietemp' defined in zephyr/dts/arm/st/h7rs/stm32h7rs.dtsi:956 */
	die_temp: dietemp {
		compatible = "st,stm32-temp-cal"; /* in zephyr/dts/arm/st/h7rs/stm32h7rs.dtsi:957 */
		ts-cal1-addr = < 0x8fff814 >;     /* in zephyr/dts/arm/st/h7rs/stm32h7rs.dtsi:958 */
		ts-cal2-addr = < 0x8fff818 >;     /* in zephyr/dts/arm/st/h7rs/stm32h7rs.dtsi:959 */
		ts-cal1-temp = < 0x1e >;          /* in zephyr/dts/arm/st/h7rs/stm32h7rs.dtsi:960 */
		ts-cal2-temp = < 0x82 >;          /* in zephyr/dts/arm/st/h7rs/stm32h7rs.dtsi:961 */
		ts-cal-vrefanalog = < 0xce4 >;    /* in zephyr/dts/arm/st/h7rs/stm32h7rs.dtsi:962 */
		ts-cal-resolution = < 0xc >;      /* in zephyr/dts/arm/st/h7rs/stm32h7rs.dtsi:963 */
		io-channels = < &adc1 0x10 >;     /* in zephyr/dts/arm/st/h7rs/stm32h7rs.dtsi:964 */
		status = "disabled";              /* in zephyr/dts/arm/st/h7rs/stm32h7rs.dtsi:965 */
	};

	/* node '/vbat' defined in zephyr/dts/arm/st/h7rs/stm32h7rs.dtsi:968 */
	vbat: vbat {
		compatible = "st,stm32-vbat"; /* in zephyr/dts/arm/st/h7rs/stm32h7rs.dtsi:969 */
		ratio = < 0x4 >;              /* in zephyr/dts/arm/st/h7rs/stm32h7rs.dtsi:970 */
		io-channels = < &adc2 0x10 >; /* in zephyr/dts/arm/st/h7rs/stm32h7rs.dtsi:972 */
		status = "okay";              /* in zephyr/boards/ruiside/art_pi2/art_pi2.dts:118 */
	};

	/* node '/vref' defined in zephyr/dts/arm/st/h7rs/stm32h7rs.dtsi:975 */
	vref: vref {
		compatible = "st,stm32-vref";     /* in zephyr/dts/arm/st/h7rs/stm32h7rs.dtsi:976 */
		vrefint-cal-addr = < 0x8fff810 >; /* in zephyr/dts/arm/st/h7rs/stm32h7rs.dtsi:977 */
		vrefint-cal-mv = < 0xce4 >;       /* in zephyr/dts/arm/st/h7rs/stm32h7rs.dtsi:978 */
		io-channels = < &adc1 0x11 >;     /* in zephyr/dts/arm/st/h7rs/stm32h7rs.dtsi:980 */
		status = "okay";                  /* in zephyr/boards/ruiside/art_pi2/art_pi2.dts:114 */
	};

	/* node '/leds' defined in zephyr/boards/ruiside/art_pi2/art_pi2.dts:23 */
	leds: leds {
		compatible = "gpio-leds"; /* in zephyr/boards/ruiside/art_pi2/art_pi2.dts:24 */

		/* node '/leds/led_1' defined in zephyr/boards/ruiside/art_pi2/art_pi2.dts:26 */
		red_led: led_1 {
			gpios = < &gpioo 0x1 0x0 >; /* in zephyr/boards/ruiside/art_pi2/art_pi2.dts:27 */
			label = "User LED1";        /* in zephyr/boards/ruiside/art_pi2/art_pi2.dts:28 */
		};

		/* node '/leds/led_2' defined in zephyr/boards/ruiside/art_pi2/art_pi2.dts:31 */
		blue_led: led_2 {
			gpios = < &gpioo 0x5 0x1 >; /* in zephyr/boards/ruiside/art_pi2/art_pi2.dts:32 */
			label = "User LED2";        /* in zephyr/boards/ruiside/art_pi2/art_pi2.dts:33 */
		};
	};

	/* node '/gpio_keys' defined in zephyr/boards/ruiside/art_pi2/art_pi2.dts:37 */
	gpio_keys {
		compatible = "gpio-keys"; /* in zephyr/boards/ruiside/art_pi2/art_pi2.dts:38 */

		/* node '/gpio_keys/button_0' defined in zephyr/boards/ruiside/art_pi2/art_pi2.dts:40 */
		user_button: button_0 {
			label = "User";             /* in zephyr/boards/ruiside/art_pi2/art_pi2.dts:41 */
			gpios = < &gpioc 0xd 0x1 >; /* in zephyr/boards/ruiside/art_pi2/art_pi2.dts:42 */
			zephyr,code = < 0xb >;      /* in zephyr/boards/ruiside/art_pi2/art_pi2.dts:43 */
		};
	};
};
